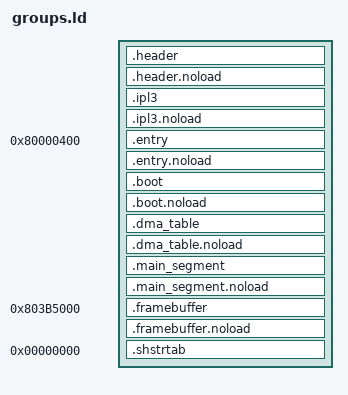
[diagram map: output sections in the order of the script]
SECTIONS
{
    __romPos = 0x0;

    header_ROM_START = __romPos;
    header_VRAM = ADDR(.header);
    header_alloc_VRAM = .;

    .header : AT(header_ROM_START) SUBALIGN(16)
    {
        FILL(0x00000000);
        header_TEXT_START = .;
        build/src/rom_header/rom_header.o(.text*);
        . = ALIGN(., 0x10);
        header_TEXT_END = .;
        header_TEXT_SIZE = ABSOLUTE(header_TEXT_END - header_TEXT_START);

        header_DATA_START = .;
        build/src/rom_header/rom_header.o(.data*);
        . = ALIGN(., 0x10);
        header_DATA_END = .;
        header_DATA_SIZE = ABSOLUTE(header_DATA_END - header_DATA_START);

        header_RODATA_START = .;
        build/src/rom_header/rom_header.o(.rodata*);
        . = ALIGN(., 0x10);
        header_RODATA_END = .;
        header_RODATA_SIZE = ABSOLUTE(header_RODATA_END - header_RODATA_START);

        header_SDATA_START = .;
        build/src/rom_header/rom_header.o(.sdata*);
        . = ALIGN(., 0x10);
        header_SDATA_END = .;
        header_SDATA_SIZE = ABSOLUTE(header_SDATA_END - header_SDATA_START);
    }

    header_alloc_VRAM_END = .;
    header_alloc_VRAM_SIZE = ABSOLUTE(header_alloc_VRAM_END - header_alloc_VRAM);

    header_noload_VRAM = .;

    .header.noload (NOLOAD) : SUBALIGN(16)
    {
        FILL(0x00000000);
        header_SBSS_START = .;
        build/src/rom_header/rom_header.o(.sbss*);
        . = ALIGN(., 0x10);
        header_SBSS_END = .;
        header_SBSS_SIZE = ABSOLUTE(header_SBSS_END - header_SBSS_START);

        header_SCOMMON_START = .;
        build/src/rom_header/rom_header.o(.scommon*);
        . = ALIGN(., 0x10);
        header_SCOMMON_END = .;
        header_SCOMMON_SIZE = ABSOLUTE(header_SCOMMON_END - header_SCOMMON_START);

        header_BSS_START = .;
        build/src/rom_header/rom_header.o(.bss*);
        . = ALIGN(., 0x10);
        header_BSS_END = .;
        header_BSS_SIZE = ABSOLUTE(header_BSS_END - header_BSS_START);

        headerCOMMON_START = .;
        build/src/rom_header/rom_header.o(COMMON*);
        . = ALIGN(., 0x10);
        headerCOMMON_END = .;
        headerCOMMON_SIZE = ABSOLUTE(headerCOMMON_END - headerCOMMON_START);
    }

    header_noload_VRAM_END = .;
    header_noload_VRAM_SIZE = ABSOLUTE(header_noload_VRAM_END - header_noload_VRAM);
    header_VRAM_END = .;
    header_VRAM_SIZE = ABSOLUTE(header_VRAM_END - header_VRAM);
    __romPos += SIZEOF(.header);
    header_ROM_END = __romPos;
    header_ROM_SIZE = ABSOLUTE(header_ROM_END - header_ROM_START);

    ipl3_ROM_START = __romPos;
    ipl3_VRAM = ADDR(.ipl3);
    ipl3_alloc_VRAM = .;

    .ipl3 : AT(ipl3_ROM_START) SUBALIGN(16)
    {
        FILL(0x00000000);
        ipl3_TEXT_START = .;
        build/asm/data/ipl3.o(.text*);
        . = ALIGN(., 0x10);
        ipl3_TEXT_END = .;
        ipl3_TEXT_SIZE = ABSOLUTE(ipl3_TEXT_END - ipl3_TEXT_START);

        ipl3_DATA_START = .;
        build/asm/data/ipl3.o(.data*);
        . = ALIGN(., 0x10);
        ipl3_DATA_END = .;
        ipl3_DATA_SIZE = ABSOLUTE(ipl3_DATA_END - ipl3_DATA_START);

        ipl3_RODATA_START = .;
        build/asm/data/ipl3.o(.rodata*);
        . = ALIGN(., 0x10);
        ipl3_RODATA_END = .;
        ipl3_RODATA_SIZE = ABSOLUTE(ipl3_RODATA_END - ipl3_RODATA_START);

        ipl3_SDATA_START = .;
        build/asm/data/ipl3.o(.sdata*);
        . = ALIGN(., 0x10);
        ipl3_SDATA_END = .;
        ipl3_SDATA_SIZE = ABSOLUTE(ipl3_SDATA_END - ipl3_SDATA_START);
    }

    ipl3_alloc_VRAM_END = .;
    ipl3_alloc_VRAM_SIZE = ABSOLUTE(ipl3_alloc_VRAM_END - ipl3_alloc_VRAM);

    ipl3_noload_VRAM = .;

    .ipl3.noload (NOLOAD) : SUBALIGN(16)
    {
        FILL(0x00000000);
        ipl3_SBSS_START = .;
        build/asm/data/ipl3.o(.sbss*);
        . = ALIGN(., 0x10);
        ipl3_SBSS_END = .;
        ipl3_SBSS_SIZE = ABSOLUTE(ipl3_SBSS_END - ipl3_SBSS_START);

        ipl3_SCOMMON_START = .;
        build/asm/data/ipl3.o(.scommon*);
        . = ALIGN(., 0x10);
        ipl3_SCOMMON_END = .;
        ipl3_SCOMMON_SIZE = ABSOLUTE(ipl3_SCOMMON_END - ipl3_SCOMMON_START);

        ipl3_BSS_START = .;
        build/asm/data/ipl3.o(.bss*);
        . = ALIGN(., 0x10);
        ipl3_BSS_END = .;
        ipl3_BSS_SIZE = ABSOLUTE(ipl3_BSS_END - ipl3_BSS_START);

        ipl3COMMON_START = .;
        build/asm/data/ipl3.o(COMMON*);
        . = ALIGN(., 0x10);
        ipl3COMMON_END = .;
        ipl3COMMON_SIZE = ABSOLUTE(ipl3COMMON_END - ipl3COMMON_START);
    }

    ipl3_noload_VRAM_END = .;
    ipl3_noload_VRAM_SIZE = ABSOLUTE(ipl3_noload_VRAM_END - ipl3_noload_VRAM);
    ipl3_VRAM_END = .;
    ipl3_VRAM_SIZE = ABSOLUTE(ipl3_VRAM_END - ipl3_VRAM);
    __romPos += SIZEOF(.ipl3);
    ipl3_ROM_END = __romPos;
    ipl3_ROM_SIZE = ABSOLUTE(ipl3_ROM_END - ipl3_ROM_START);

    entry_ROM_START = __romPos;
    entry_VRAM = ADDR(.entry);
    entry_alloc_VRAM = .;

    .entry 0x80000400 : AT(entry_ROM_START) SUBALIGN(16)
    {
        FILL(0x00000000);
        entry_TEXT_START = .;
        build/src/entry/entry.o(.text*);
        . = ALIGN(., 0x10);
        entry_TEXT_END = .;
        entry_TEXT_SIZE = ABSOLUTE(entry_TEXT_END - entry_TEXT_START);

        entry_DATA_START = .;
        build/src/entry/entry.o(.data*);
        . = ALIGN(., 0x10);
        entry_DATA_END = .;
        entry_DATA_SIZE = ABSOLUTE(entry_DATA_END - entry_DATA_START);

        entry_RODATA_START = .;
        build/src/entry/entry.o(.rodata*);
        . = ALIGN(., 0x10);
        entry_RODATA_END = .;
        entry_RODATA_SIZE = ABSOLUTE(entry_RODATA_END - entry_RODATA_START);

        entry_SDATA_START = .;
        build/src/entry/entry.o(.sdata*);
        . = ALIGN(., 0x10);
        entry_SDATA_END = .;
        entry_SDATA_SIZE = ABSOLUTE(entry_SDATA_END - entry_SDATA_START);
    }

    entry_alloc_VRAM_END = .;
    entry_alloc_VRAM_SIZE = ABSOLUTE(entry_alloc_VRAM_END - entry_alloc_VRAM);

    entry_noload_VRAM = .;

    .entry.noload (NOLOAD) : SUBALIGN(16)
    {
        FILL(0x00000000);
        entry_SBSS_START = .;
        build/src/entry/entry.o(.sbss*);
        . = ALIGN(., 0x10);
        entry_SBSS_END = .;
        entry_SBSS_SIZE = ABSOLUTE(entry_SBSS_END - entry_SBSS_START);

        entry_SCOMMON_START = .;
        build/src/entry/entry.o(.scommon*);
        . = ALIGN(., 0x10);
        entry_SCOMMON_END = .;
        entry_SCOMMON_SIZE = ABSOLUTE(entry_SCOMMON_END - entry_SCOMMON_START);

        entry_BSS_START = .;
        build/src/entry/entry.o(.bss*);
        . = ALIGN(., 0x10);
        entry_BSS_END = .;
        entry_BSS_SIZE = ABSOLUTE(entry_BSS_END - entry_BSS_START);

        entryCOMMON_START = .;
        build/src/entry/entry.o(COMMON*);
        . = ALIGN(., 0x10);
        entryCOMMON_END = .;
        entryCOMMON_SIZE = ABSOLUTE(entryCOMMON_END - entryCOMMON_START);
    }

    entry_noload_VRAM_END = .;
    entry_noload_VRAM_SIZE = ABSOLUTE(entry_noload_VRAM_END - entry_noload_VRAM);
    entry_VRAM_END = .;
    entry_VRAM_SIZE = ABSOLUTE(entry_VRAM_END - entry_VRAM);
    __romPos += SIZEOF(.entry);
    entry_ROM_END = __romPos;
    entry_ROM_SIZE = ABSOLUTE(entry_ROM_END - entry_ROM_START);

    boot_ROM_START = __romPos;
    boot_VRAM = ADDR(.boot);
    boot_alloc_VRAM = .;

    .boot : AT(boot_ROM_START) SUBALIGN(16)
    {
        FILL(0x00000000);
        boot_TEXT_START = .;
        build/src/boot/boot_main.o(.text*);
        build/src/boot/util.o(.text*);
        build/src/libultra/io/conteepprobe.o(.text*);
        build/src/libultra/io/conteeplongwrite.o(.text*);
        build/src/libultra/io/conteeplongread.o(.text*);
        build/src/libultra/io/pimgr.o(.text*);
        build/src/libultra/io/epirawdma.o(.text*);
        build/src/libultra/io/epidma.o(.text*);
        build/src/libultra/io/cartrominit.o(.text*);
        build/src/libultra/io/devmgr.o(.text*);
        build/src/libultra/io/piacs.o(.text*);
        build/src/libultra/io/pidma.o(.text*);
        build/src/libultra/io/aigetlen.o(.text*);
        build/src/libultra/io/aigetstat.o(.text*);
        build/src/libultra/io/aisetfreq.o(.text*);
        build/src/libultra/io/aisetnextbuf.o(.text*);
        build/src/libultra/audio/env.o(.text*);
        build/src/libultra/audio/sl.o(.text*);
        build/src/libultra/audio/heapinit.o(.text*);
        build/src/libultra/audio/synthesizer.o(.text*);
        build/src/libultra/audio/syndelete.o(.text*);
        build/src/libultra/audio/synaddplayer.o(.text*);
        build/src/libultra/audio/synallocvoice.o(.text*);
        build/src/libultra/audio/synstopvoice.o(.text*);
        build/src/libultra/audio/synstartvoice.o(.text*);
        build/src/libultra/audio/synsetpitch.o(.text*);
        build/src/libultra/audio/synsetvol.o(.text*);
        build/src/libultra/audio/synsetfxmix.o(.text*);
        build/src/libultra/audio/synsetpan.o(.text*);
        build/src/libultra/audio/synallocfx.o(.text*);
        build/src/libultra/os/invaldcache.o(.text*);
        build/src/libultra/os/writebackdcacheall.o(.text*);
        build/src/libultra/io/contquery.o(.text*);
        build/src/libultra/io/contreaddata.o(.text*);
        build/src/libultra/io/controller.o(.text*);
        build/src/libultra/io/contsetch.o(.text*);
        build/src/libultra/os/virtualtophysical.o(.text*);
        build/src/libultra/gu/sqrtf.o(.text*);
        build/src/libultra/gu/cosf.o(.text*);
        build/src/libultra/gu/ortho.o(.text*);
        build/src/libultra/gu/perspective.o(.text*);
        build/src/libultra/gu/rotaterpy.o(.text*);
        build/src/libultra/gu/sinf.o(.text*);
        build/src/libultra/gu/sins.o(.text*);
        build/src/libultra/libc/bcmp.o(.text*);
        build/src/libultra/libc/bcopy.o(.text*);
        build/src/libultra/libc/bzero.o(.text*);
        build/src/libultra/libc/string.o(.text*);
        build/src/libultra/os/createmesgqueue.o(.text*);
        build/src/libultra/os/jammesg.o(.text*);
        build/src/libultra/os/recvmesg.o(.text*);
        build/src/libultra/os/sendmesg.o(.text*);
        build/src/libultra/os/seteventmesg.o(.text*);
        build/src/libultra/io/sptask.o(.text*);
        build/src/libultra/io/sptaskyield.o(.text*);
        build/src/libultra/io/sptaskyielded.o(.text*);
        build/src/libultra/sched/sched.o(.text*);
        build/src/libultra/io/sirawdma.o(.text*);
        build/src/libultra/io/siacs.o(.text*);
        build/src/libultra/os/createthread.o(.text*);
        build/src/libultra/os/getthreadpri.o(.text*);
        build/src/libultra/os/setthreadpri.o(.text*);
        build/src/libultra/os/startthread.o(.text*);
        build/src/libultra/os/stopthread.o(.text*);
        build/src/libultra/os/thread.o(.text*);
        build/src/libultra/os/yieldthread.o(.text*);
        build/src/libultra/os/gettime.o(.text*);
        build/src/libultra/os/settime.o(.text*);
        build/src/libultra/os/settimer.o(.text*);
        build/src/libultra/os/timerintr.o(.text*);
        build/src/libultra/os/probetlb.o(.text*);
        build/src/libultra/io/vigetcurrframebuf.o(.text*);
        build/src/libultra/io/vigetnextframebuf.o(.text*);
        build/src/libultra/io/vimgr.o(.text*);
        build/src/libultra/io/vitbl.o(.text*);
        build/src/libultra/io/visetevent.o(.text*);
        build/src/libultra/io/visetmode.o(.text*);
        build/src/libultra/io/visetspecial.o(.text*);
        build/src/libultra/io/visetyscale.o(.text*);
        build/src/libultra/io/viswapbuf.o(.text*);
        build/src/libultra/io/viswapcontext.o(.text*);
        build/src/libultra/io/viblack.o(.text*);
        build/src/libultra/mgu/mtxident.o(.text*);
        build/src/libultra/mgu/mtxidentf.o(.text*);
        build/src/libultra/mgu/mtxf2l.o(.text*);
        build/src/libultra/mgu/mtxl2f.o(.text*);
        build/src/libultra/mgu/mtxcatf.o(.text*);
        build/src/libultra/mgu/scale.o(.text*);
        build/src/libultra/mgu/scalef.o(.text*);
        build/src/libultra/mgu/translate.o(.text*);
        build/src/libultra/mgu/translatef.o(.text*);
        build/src/libultra/os/initialize.o(.text*);
        build/src/libultra/io/conteepread.o(.text*);
        build/src/libultra/io/conteepwrite.o(.text*);
        build/src/libultra/os/exceptasm.o(.text*);
        build/src/libultra/os/interrupt.o(.text*);
        build/src/libultra/os/setintmask.o(.text*);
        build/src/libultra/os/setglobalintmask.o(.text*);
        build/src/libultra/os/resetglobalintmask.o(.text*);
        build/src/libultra/io/pirawdma.o(.text*);
        build/src/libultra/io/pigetcmdq.o(.text*);
        build/src/libultra/io/epirawread.o(.text*);
        build/src/libultra/io/epirawwrite.o(.text*);
        build/src/libultra/io/ai.o(.text*);
        build/src/libultra/audio/drvrnew.o(.text*);
        build/src/libultra/audio/load.o(.text*);
        build/src/libultra/audio/auxbus.o(.text*);
        build/src/libultra/audio/filter.o(.text*);
        build/src/libultra/audio/mainbus.o(.text*);
        build/src/libultra/audio/resample.o(.text*);
        build/src/libultra/audio/reverb.o(.text*);
        build/src/libultra/audio/save.o(.text*);
        build/src/libultra/audio/heapalloc.o(.text*);
        build/src/libultra/audio/copy.o(.text*);
        build/src/libultra/os/invalicache.o(.text*);
        build/src/libultra/os/writebackdcache.o(.text*);
        build/src/libultra/io/dpsetnextbuf.o(.text*);
        build/src/libultra/os/getcause.o(.text*);
        build/src/libultra/os/getcount.o(.text*);
        build/src/libultra/os/getsr.o(.text*);
        build/src/libultra/os/setcompare.o(.text*);
        build/src/libultra/os/setfpccsr.o(.text*);
        build/src/libultra/os/setsr.o(.text*);
        build/src/libultra/os/setwatchlo.o(.text*);
        build/src/libultra/io/sp.o(.text*);
        build/src/libultra/io/spgetstat.o(.text*);
        build/src/libultra/io/spsetstat.o(.text*);
        build/src/libultra/io/spsetpc.o(.text*);
        build/src/libultra/io/sprawdma.o(.text*);
        build/src/libultra/io/sirawread.o(.text*);
        build/src/libultra/io/sirawwrite.o(.text*);
        build/src/libultra/os/destroythread.o(.text*);
        build/src/libultra/os/maptlbrdb.o(.text*);
        build/src/libultra/os/unmaptlball.o(.text*);
        build/src/libultra/io/vi.o(.text*);
        build/src/libultra/io/vigetcurrcontext.o(.text*);
        build/src/libultra/vimodes/vimodentsclan1.o(.text*);
        build/src/libultra/vimodes/vimodepallan1.o(.text*);
        build/src/libultra/vimodes/vimodempallan1.o(.text*);
        build/src/libultra/os/parameters.o(.text*);
        build/src/libultra/gu/libm_vals.o(.text*);
        build/src/libultra/io/dp.o(.text*);
        build/src/libultra/io/si.o(.text*);
        build/src/libkmc/fmod.o(.text*);
        build/src/libkmc/memmove.o(.text*);
        build/src/libkmc/memset.o(.text*);
        build/src/libkmc/modf.o(.text*);
        build/src/libkmc/rand.o(.text*);
        build/src/libkmc/strcpy.o(.text*);
        build/src/libkmc/mmuldi3.o(.text*);
        build/src/libkmc/ctype.o(.text*);
        . = ALIGN(., 0x10);
        boot_TEXT_END = .;
        boot_TEXT_SIZE = ABSOLUTE(boot_TEXT_END - boot_TEXT_START);

        boot_DATA_START = .;
        build/src/boot/boot_main.o(.data*);
        build/src/boot/util.o(.data*);
        build/src/libultra/io/conteepprobe.o(.data*);
        build/src/libultra/io/conteeplongwrite.o(.data*);
        build/src/libultra/io/conteeplongread.o(.data*);
        build/src/libultra/io/pimgr.o(.data*);
        build/src/libultra/io/epirawdma.o(.data*);
        build/src/libultra/io/epidma.o(.data*);
        build/src/libultra/io/cartrominit.o(.data*);
        build/src/libultra/io/devmgr.o(.data*);
        build/src/libultra/io/piacs.o(.data*);
        build/src/libultra/io/pidma.o(.data*);
        build/src/libultra/io/aigetlen.o(.data*);
        build/src/libultra/io/aigetstat.o(.data*);
        build/src/libultra/io/aisetfreq.o(.data*);
        build/src/libultra/io/aisetnextbuf.o(.data*);
        build/src/libultra/audio/env.o(.data*);
        build/src/libultra/audio/sl.o(.data*);
        build/src/libultra/audio/heapinit.o(.data*);
        build/src/libultra/audio/synthesizer.o(.data*);
        build/src/libultra/audio/syndelete.o(.data*);
        build/src/libultra/audio/synaddplayer.o(.data*);
        build/src/libultra/audio/synallocvoice.o(.data*);
        build/src/libultra/audio/synstopvoice.o(.data*);
        build/src/libultra/audio/synstartvoice.o(.data*);
        build/src/libultra/audio/synsetpitch.o(.data*);
        build/src/libultra/audio/synsetvol.o(.data*);
        build/src/libultra/audio/synsetfxmix.o(.data*);
        build/src/libultra/audio/synsetpan.o(.data*);
        build/src/libultra/audio/synallocfx.o(.data*);
        build/src/libultra/os/invaldcache.o(.data*);
        build/src/libultra/os/writebackdcacheall.o(.data*);
        build/src/libultra/io/contquery.o(.data*);
        build/src/libultra/io/contreaddata.o(.data*);
        build/src/libultra/io/controller.o(.data*);
        build/src/libultra/io/contsetch.o(.data*);
        build/src/libultra/os/virtualtophysical.o(.data*);
        build/src/libultra/gu/sqrtf.o(.data*);
        build/src/libultra/gu/cosf.o(.data*);
        build/src/libultra/gu/ortho.o(.data*);
        build/src/libultra/gu/perspective.o(.data*);
        build/src/libultra/gu/rotaterpy.o(.data*);
        build/src/libultra/gu/sinf.o(.data*);
        build/src/libultra/gu/sins.o(.data*);
        build/src/libultra/libc/bcmp.o(.data*);
        build/src/libultra/libc/bcopy.o(.data*);
        build/src/libultra/libc/bzero.o(.data*);
        build/src/libultra/libc/string.o(.data*);
        build/src/libultra/os/createmesgqueue.o(.data*);
        build/src/libultra/os/jammesg.o(.data*);
        build/src/libultra/os/recvmesg.o(.data*);
        build/src/libultra/os/sendmesg.o(.data*);
        build/src/libultra/os/seteventmesg.o(.data*);
        build/src/libultra/io/sptask.o(.data*);
        build/src/libultra/io/sptaskyield.o(.data*);
        build/src/libultra/io/sptaskyielded.o(.data*);
        build/src/libultra/sched/sched.o(.data*);
        build/src/libultra/io/sirawdma.o(.data*);
        build/src/libultra/io/siacs.o(.data*);
        build/src/libultra/os/createthread.o(.data*);
        build/src/libultra/os/getthreadpri.o(.data*);
        build/src/libultra/os/setthreadpri.o(.data*);
        build/src/libultra/os/startthread.o(.data*);
        build/src/libultra/os/stopthread.o(.data*);
        build/src/libultra/os/thread.o(.data*);
        build/src/libultra/os/yieldthread.o(.data*);
        build/src/libultra/os/gettime.o(.data*);
        build/src/libultra/os/settime.o(.data*);
        build/src/libultra/os/settimer.o(.data*);
        build/src/libultra/os/timerintr.o(.data*);
        build/src/libultra/os/probetlb.o(.data*);
        build/src/libultra/io/vigetcurrframebuf.o(.data*);
        build/src/libultra/io/vigetnextframebuf.o(.data*);
        build/src/libultra/io/vimgr.o(.data*);
        build/src/libultra/io/vitbl.o(.data*);
        build/src/libultra/io/visetevent.o(.data*);
        build/src/libultra/io/visetmode.o(.data*);
        build/src/libultra/io/visetspecial.o(.data*);
        build/src/libultra/io/visetyscale.o(.data*);
        build/src/libultra/io/viswapbuf.o(.data*);
        build/src/libultra/io/viswapcontext.o(.data*);
        build/src/libultra/io/viblack.o(.data*);
        build/src/libultra/mgu/mtxident.o(.data*);
        build/src/libultra/mgu/mtxidentf.o(.data*);
        build/src/libultra/mgu/mtxf2l.o(.data*);
        build/src/libultra/mgu/mtxl2f.o(.data*);
        build/src/libultra/mgu/mtxcatf.o(.data*);
        build/src/libultra/mgu/scale.o(.data*);
        build/src/libultra/mgu/scalef.o(.data*);
        build/src/libultra/mgu/translate.o(.data*);
        build/src/libultra/mgu/translatef.o(.data*);
        build/src/libultra/os/initialize.o(.data*);
        build/src/libultra/io/conteepread.o(.data*);
        build/src/libultra/io/conteepwrite.o(.data*);
        build/src/libultra/os/exceptasm.o(.data*);
        build/src/libultra/os/interrupt.o(.data*);
        build/src/libultra/os/setintmask.o(.data*);
        build/src/libultra/os/setglobalintmask.o(.data*);
        build/src/libultra/os/resetglobalintmask.o(.data*);
        build/src/libultra/io/pirawdma.o(.data*);
        build/src/libultra/io/pigetcmdq.o(.data*);
        build/src/libultra/io/epirawread.o(.data*);
        build/src/libultra/io/epirawwrite.o(.data*);
        build/src/libultra/io/ai.o(.data*);
        build/src/libultra/audio/drvrnew.o(.data*);
        build/src/libultra/audio/load.o(.data*);
        build/src/libultra/audio/auxbus.o(.data*);
        build/src/libultra/audio/filter.o(.data*);
        build/src/libultra/audio/mainbus.o(.data*);
        build/src/libultra/audio/resample.o(.data*);
        build/src/libultra/audio/reverb.o(.data*);
        build/src/libultra/audio/save.o(.data*);
        build/src/libultra/audio/heapalloc.o(.data*);
        build/src/libultra/audio/copy.o(.data*);
        build/src/libultra/os/invalicache.o(.data*);
        build/src/libultra/os/writebackdcache.o(.data*);
        build/src/libultra/io/dpsetnextbuf.o(.data*);
        build/src/libultra/os/getcause.o(.data*);
        build/src/libultra/os/getcount.o(.data*);
        build/src/libultra/os/getsr.o(.data*);
        build/src/libultra/os/setcompare.o(.data*);
        build/src/libultra/os/setfpccsr.o(.data*);
        build/src/libultra/os/setsr.o(.data*);
        build/src/libultra/os/setwatchlo.o(.data*);
        build/src/libultra/io/sp.o(.data*);
        build/src/libultra/io/spgetstat.o(.data*);
        build/src/libultra/io/spsetstat.o(.data*);
        build/src/libultra/io/spsetpc.o(.data*);
        build/src/libultra/io/sprawdma.o(.data*);
        build/src/libultra/io/sirawread.o(.data*);
        build/src/libultra/io/sirawwrite.o(.data*);
        build/src/libultra/os/destroythread.o(.data*);
        build/src/libultra/os/maptlbrdb.o(.data*);
        build/src/libultra/os/unmaptlball.o(.data*);
        build/src/libultra/io/vi.o(.data*);
        build/src/libultra/io/vigetcurrcontext.o(.data*);
        build/src/libultra/vimodes/vimodentsclan1.o(.data*);
        build/src/libultra/vimodes/vimodepallan1.o(.data*);
        build/src/libultra/vimodes/vimodempallan1.o(.data*);
        build/src/libultra/os/parameters.o(.data*);
        build/src/libultra/gu/libm_vals.o(.data*);
        build/src/libultra/io/dp.o(.data*);
        build/src/libultra/io/si.o(.data*);
        build/src/libkmc/fmod.o(.data*);
        build/src/libkmc/memmove.o(.data*);
        build/src/libkmc/memset.o(.data*);
        build/src/libkmc/modf.o(.data*);
        build/src/libkmc/rand.o(.data*);
        build/src/libkmc/strcpy.o(.data*);
        build/src/libkmc/mmuldi3.o(.data*);
        build/src/libkmc/ctype.o(.data*);
        . = ALIGN(., 0x10);
        boot_DATA_END = .;
        boot_DATA_SIZE = ABSOLUTE(boot_DATA_END - boot_DATA_START);

        boot_RODATA_START = .;
        build/src/boot/boot_main.o(.rodata*);
        build/src/boot/util.o(.rodata*);
        build/src/libultra/io/conteepprobe.o(.rodata*);
        build/src/libultra/io/conteeplongwrite.o(.rodata*);
        build/src/libultra/io/conteeplongread.o(.rodata*);
        build/src/libultra/io/pimgr.o(.rodata*);
        build/src/libultra/io/epirawdma.o(.rodata*);
        build/src/libultra/io/epidma.o(.rodata*);
        build/src/libultra/io/cartrominit.o(.rodata*);
        build/src/libultra/io/devmgr.o(.rodata*);
        build/src/libultra/io/piacs.o(.rodata*);
        build/src/libultra/io/pidma.o(.rodata*);
        build/src/libultra/io/aigetlen.o(.rodata*);
        build/src/libultra/io/aigetstat.o(.rodata*);
        build/src/libultra/io/aisetfreq.o(.rodata*);
        build/src/libultra/io/aisetnextbuf.o(.rodata*);
        build/src/libultra/audio/env.o(.rodata*);
        build/src/libultra/audio/sl.o(.rodata*);
        build/src/libultra/audio/heapinit.o(.rodata*);
        build/src/libultra/audio/synthesizer.o(.rodata*);
        build/src/libultra/audio/syndelete.o(.rodata*);
        build/src/libultra/audio/synaddplayer.o(.rodata*);
        build/src/libultra/audio/synallocvoice.o(.rodata*);
        build/src/libultra/audio/synstopvoice.o(.rodata*);
        build/src/libultra/audio/synstartvoice.o(.rodata*);
        build/src/libultra/audio/synsetpitch.o(.rodata*);
        build/src/libultra/audio/synsetvol.o(.rodata*);
        build/src/libultra/audio/synsetfxmix.o(.rodata*);
        build/src/libultra/audio/synsetpan.o(.rodata*);
        build/src/libultra/audio/synallocfx.o(.rodata*);
        build/src/libultra/os/invaldcache.o(.rodata*);
        build/src/libultra/os/writebackdcacheall.o(.rodata*);
        build/src/libultra/io/contquery.o(.rodata*);
        build/src/libultra/io/contreaddata.o(.rodata*);
        build/src/libultra/io/controller.o(.rodata*);
        build/src/libultra/io/contsetch.o(.rodata*);
        build/src/libultra/os/virtualtophysical.o(.rodata*);
        build/src/libultra/gu/sqrtf.o(.rodata*);
        build/src/libultra/gu/cosf.o(.rodata*);
        build/src/libultra/gu/ortho.o(.rodata*);
        build/src/libultra/gu/perspective.o(.rodata*);
        build/src/libultra/gu/rotaterpy.o(.rodata*);
        build/src/libultra/gu/sinf.o(.rodata*);
        build/src/libultra/gu/sins.o(.rodata*);
        build/src/libultra/libc/bcmp.o(.rodata*);
        build/src/libultra/libc/bcopy.o(.rodata*);
        build/src/libultra/libc/bzero.o(.rodata*);
        build/src/libultra/libc/string.o(.rodata*);
        build/src/libultra/os/createmesgqueue.o(.rodata*);
        build/src/libultra/os/jammesg.o(.rodata*);
        build/src/libultra/os/recvmesg.o(.rodata*);
        build/src/libultra/os/sendmesg.o(.rodata*);
        build/src/libultra/os/seteventmesg.o(.rodata*);
        build/src/libultra/io/sptask.o(.rodata*);
        build/src/libultra/io/sptaskyield.o(.rodata*);
        build/src/libultra/io/sptaskyielded.o(.rodata*);
        build/src/libultra/sched/sched.o(.rodata*);
        build/src/libultra/io/sirawdma.o(.rodata*);
        build/src/libultra/io/siacs.o(.rodata*);
        build/src/libultra/os/createthread.o(.rodata*);
        build/src/libultra/os/getthreadpri.o(.rodata*);
        build/src/libultra/os/setthreadpri.o(.rodata*);
        build/src/libultra/os/startthread.o(.rodata*);
        build/src/libultra/os/stopthread.o(.rodata*);
        build/src/libultra/os/thread.o(.rodata*);
        build/src/libultra/os/yieldthread.o(.rodata*);
        build/src/libultra/os/gettime.o(.rodata*);
        build/src/libultra/os/settime.o(.rodata*);
        build/src/libultra/os/settimer.o(.rodata*);
        build/src/libultra/os/timerintr.o(.rodata*);
        build/src/libultra/os/probetlb.o(.rodata*);
        build/src/libultra/io/vigetcurrframebuf.o(.rodata*);
        build/src/libultra/io/vigetnextframebuf.o(.rodata*);
        build/src/libultra/io/vimgr.o(.rodata*);
        build/src/libultra/io/vitbl.o(.rodata*);
        build/src/libultra/io/visetevent.o(.rodata*);
        build/src/libultra/io/visetmode.o(.rodata*);
        build/src/libultra/io/visetspecial.o(.rodata*);
        build/src/libultra/io/visetyscale.o(.rodata*);
        build/src/libultra/io/viswapbuf.o(.rodata*);
        build/src/libultra/io/viswapcontext.o(.rodata*);
        build/src/libultra/io/viblack.o(.rodata*);
        build/src/libultra/mgu/mtxident.o(.rodata*);
        build/src/libultra/mgu/mtxidentf.o(.rodata*);
        build/src/libultra/mgu/mtxf2l.o(.rodata*);
        build/src/libultra/mgu/mtxl2f.o(.rodata*);
        build/src/libultra/mgu/mtxcatf.o(.rodata*);
        build/src/libultra/mgu/scale.o(.rodata*);
        build/src/libultra/mgu/scalef.o(.rodata*);
        build/src/libultra/mgu/translate.o(.rodata*);
        build/src/libultra/mgu/translatef.o(.rodata*);
        build/src/libultra/os/initialize.o(.rodata*);
        build/src/libultra/io/conteepread.o(.rodata*);
        build/src/libultra/io/conteepwrite.o(.rodata*);
        build/src/libultra/os/exceptasm.o(.rodata*);
        build/src/libultra/os/interrupt.o(.rodata*);
        build/src/libultra/os/setintmask.o(.rodata*);
        build/src/libultra/os/setglobalintmask.o(.rodata*);
        build/src/libultra/os/resetglobalintmask.o(.rodata*);
        build/src/libultra/io/pirawdma.o(.rodata*);
        build/src/libultra/io/pigetcmdq.o(.rodata*);
        build/src/libultra/io/epirawread.o(.rodata*);
        build/src/libultra/io/epirawwrite.o(.rodata*);
        build/src/libultra/io/ai.o(.rodata*);
        build/src/libultra/audio/drvrnew.o(.rodata*);
        build/src/libultra/audio/load.o(.rodata*);
        build/src/libultra/audio/auxbus.o(.rodata*);
        build/src/libultra/audio/filter.o(.rodata*);
        build/src/libultra/audio/mainbus.o(.rodata*);
        build/src/libultra/audio/resample.o(.rodata*);
        build/src/libultra/audio/reverb.o(.rodata*);
        build/src/libultra/audio/save.o(.rodata*);
        build/src/libultra/audio/heapalloc.o(.rodata*);
        build/src/libultra/audio/copy.o(.rodata*);
        build/src/libultra/os/invalicache.o(.rodata*);
        build/src/libultra/os/writebackdcache.o(.rodata*);
        build/src/libultra/io/dpsetnextbuf.o(.rodata*);
        build/src/libultra/os/getcause.o(.rodata*);
        build/src/libultra/os/getcount.o(.rodata*);
        build/src/libultra/os/getsr.o(.rodata*);
        build/src/libultra/os/setcompare.o(.rodata*);
        build/src/libultra/os/setfpccsr.o(.rodata*);
        build/src/libultra/os/setsr.o(.rodata*);
        build/src/libultra/os/setwatchlo.o(.rodata*);
        build/src/libultra/io/sp.o(.rodata*);
        build/src/libultra/io/spgetstat.o(.rodata*);
        build/src/libultra/io/spsetstat.o(.rodata*);
        build/src/libultra/io/spsetpc.o(.rodata*);
        build/src/libultra/io/sprawdma.o(.rodata*);
        build/src/libultra/io/sirawread.o(.rodata*);
        build/src/libultra/io/sirawwrite.o(.rodata*);
        build/src/libultra/os/destroythread.o(.rodata*);
        build/src/libultra/os/maptlbrdb.o(.rodata*);
        build/src/libultra/os/unmaptlball.o(.rodata*);
        build/src/libultra/io/vi.o(.rodata*);
        build/src/libultra/io/vigetcurrcontext.o(.rodata*);
        build/src/libultra/vimodes/vimodentsclan1.o(.rodata*);
        build/src/libultra/vimodes/vimodepallan1.o(.rodata*);
        build/src/libultra/vimodes/vimodempallan1.o(.rodata*);
        build/src/libultra/os/parameters.o(.rodata*);
        build/src/libultra/gu/libm_vals.o(.rodata*);
        build/src/libultra/io/dp.o(.rodata*);
        build/src/libultra/io/si.o(.rodata*);
        build/src/libkmc/fmod.o(.rodata*);
        build/src/libkmc/memmove.o(.rodata*);
        build/src/libkmc/memset.o(.rodata*);
        build/src/libkmc/modf.o(.rodata*);
        build/src/libkmc/rand.o(.rodata*);
        build/src/libkmc/strcpy.o(.rodata*);
        build/src/libkmc/mmuldi3.o(.rodata*);
        build/src/libkmc/ctype.o(.rodata*);
        . = ALIGN(., 0x10);
        boot_RODATA_END = .;
        boot_RODATA_SIZE = ABSOLUTE(boot_RODATA_END - boot_RODATA_START);

        boot_SDATA_START = .;
        build/src/boot/boot_main.o(.sdata*);
        build/src/boot/util.o(.sdata*);
        build/src/libultra/io/conteepprobe.o(.sdata*);
        build/src/libultra/io/conteeplongwrite.o(.sdata*);
        build/src/libultra/io/conteeplongread.o(.sdata*);
        build/src/libultra/io/pimgr.o(.sdata*);
        build/src/libultra/io/epirawdma.o(.sdata*);
        build/src/libultra/io/epidma.o(.sdata*);
        build/src/libultra/io/cartrominit.o(.sdata*);
        build/src/libultra/io/devmgr.o(.sdata*);
        build/src/libultra/io/piacs.o(.sdata*);
        build/src/libultra/io/pidma.o(.sdata*);
        build/src/libultra/io/aigetlen.o(.sdata*);
        build/src/libultra/io/aigetstat.o(.sdata*);
        build/src/libultra/io/aisetfreq.o(.sdata*);
        build/src/libultra/io/aisetnextbuf.o(.sdata*);
        build/src/libultra/audio/env.o(.sdata*);
        build/src/libultra/audio/sl.o(.sdata*);
        build/src/libultra/audio/heapinit.o(.sdata*);
        build/src/libultra/audio/synthesizer.o(.sdata*);
        build/src/libultra/audio/syndelete.o(.sdata*);
        build/src/libultra/audio/synaddplayer.o(.sdata*);
        build/src/libultra/audio/synallocvoice.o(.sdata*);
        build/src/libultra/audio/synstopvoice.o(.sdata*);
        build/src/libultra/audio/synstartvoice.o(.sdata*);
        build/src/libultra/audio/synsetpitch.o(.sdata*);
        build/src/libultra/audio/synsetvol.o(.sdata*);
        build/src/libultra/audio/synsetfxmix.o(.sdata*);
        build/src/libultra/audio/synsetpan.o(.sdata*);
        build/src/libultra/audio/synallocfx.o(.sdata*);
        build/src/libultra/os/invaldcache.o(.sdata*);
        build/src/libultra/os/writebackdcacheall.o(.sdata*);
        build/src/libultra/io/contquery.o(.sdata*);
        build/src/libultra/io/contreaddata.o(.sdata*);
        build/src/libultra/io/controller.o(.sdata*);
        build/src/libultra/io/contsetch.o(.sdata*);
        build/src/libultra/os/virtualtophysical.o(.sdata*);
        build/src/libultra/gu/sqrtf.o(.sdata*);
        build/src/libultra/gu/cosf.o(.sdata*);
        build/src/libultra/gu/ortho.o(.sdata*);
        build/src/libultra/gu/perspective.o(.sdata*);
        build/src/libultra/gu/rotaterpy.o(.sdata*);
        build/src/libultra/gu/sinf.o(.sdata*);
        build/src/libultra/gu/sins.o(.sdata*);
        build/src/libultra/libc/bcmp.o(.sdata*);
        build/src/libultra/libc/bcopy.o(.sdata*);
        build/src/libultra/libc/bzero.o(.sdata*);
        build/src/libultra/libc/string.o(.sdata*);
        build/src/libultra/os/createmesgqueue.o(.sdata*);
        build/src/libultra/os/jammesg.o(.sdata*);
        build/src/libultra/os/recvmesg.o(.sdata*);
        build/src/libultra/os/sendmesg.o(.sdata*);
        build/src/libultra/os/seteventmesg.o(.sdata*);
        build/src/libultra/io/sptask.o(.sdata*);
        build/src/libultra/io/sptaskyield.o(.sdata*);
        build/src/libultra/io/sptaskyielded.o(.sdata*);
        build/src/libultra/sched/sched.o(.sdata*);
        build/src/libultra/io/sirawdma.o(.sdata*);
        build/src/libultra/io/siacs.o(.sdata*);
        build/src/libultra/os/createthread.o(.sdata*);
        build/src/libultra/os/getthreadpri.o(.sdata*);
        build/src/libultra/os/setthreadpri.o(.sdata*);
        build/src/libultra/os/startthread.o(.sdata*);
        build/src/libultra/os/stopthread.o(.sdata*);
        build/src/libultra/os/thread.o(.sdata*);
        build/src/libultra/os/yieldthread.o(.sdata*);
        build/src/libultra/os/gettime.o(.sdata*);
        build/src/libultra/os/settime.o(.sdata*);
        build/src/libultra/os/settimer.o(.sdata*);
        build/src/libultra/os/timerintr.o(.sdata*);
        build/src/libultra/os/probetlb.o(.sdata*);
        build/src/libultra/io/vigetcurrframebuf.o(.sdata*);
        build/src/libultra/io/vigetnextframebuf.o(.sdata*);
        build/src/libultra/io/vimgr.o(.sdata*);
        build/src/libultra/io/vitbl.o(.sdata*);
        build/src/libultra/io/visetevent.o(.sdata*);
        build/src/libultra/io/visetmode.o(.sdata*);
        build/src/libultra/io/visetspecial.o(.sdata*);
        build/src/libultra/io/visetyscale.o(.sdata*);
        build/src/libultra/io/viswapbuf.o(.sdata*);
        build/src/libultra/io/viswapcontext.o(.sdata*);
        build/src/libultra/io/viblack.o(.sdata*);
        build/src/libultra/mgu/mtxident.o(.sdata*);
        build/src/libultra/mgu/mtxidentf.o(.sdata*);
        build/src/libultra/mgu/mtxf2l.o(.sdata*);
        build/src/libultra/mgu/mtxl2f.o(.sdata*);
        build/src/libultra/mgu/mtxcatf.o(.sdata*);
        build/src/libultra/mgu/scale.o(.sdata*);
        build/src/libultra/mgu/scalef.o(.sdata*);
        build/src/libultra/mgu/translate.o(.sdata*);
        build/src/libultra/mgu/translatef.o(.sdata*);
        build/src/libultra/os/initialize.o(.sdata*);
        build/src/libultra/io/conteepread.o(.sdata*);
        build/src/libultra/io/conteepwrite.o(.sdata*);
        build/src/libultra/os/exceptasm.o(.sdata*);
        build/src/libultra/os/interrupt.o(.sdata*);
        build/src/libultra/os/setintmask.o(.sdata*);
        build/src/libultra/os/setglobalintmask.o(.sdata*);
        build/src/libultra/os/resetglobalintmask.o(.sdata*);
        build/src/libultra/io/pirawdma.o(.sdata*);
        build/src/libultra/io/pigetcmdq.o(.sdata*);
        build/src/libultra/io/epirawread.o(.sdata*);
        build/src/libultra/io/epirawwrite.o(.sdata*);
        build/src/libultra/io/ai.o(.sdata*);
        build/src/libultra/audio/drvrnew.o(.sdata*);
        build/src/libultra/audio/load.o(.sdata*);
        build/src/libultra/audio/auxbus.o(.sdata*);
        build/src/libultra/audio/filter.o(.sdata*);
        build/src/libultra/audio/mainbus.o(.sdata*);
        build/src/libultra/audio/resample.o(.sdata*);
        build/src/libultra/audio/reverb.o(.sdata*);
        build/src/libultra/audio/save.o(.sdata*);
        build/src/libultra/audio/heapalloc.o(.sdata*);
        build/src/libultra/audio/copy.o(.sdata*);
        build/src/libultra/os/invalicache.o(.sdata*);
        build/src/libultra/os/writebackdcache.o(.sdata*);
        build/src/libultra/io/dpsetnextbuf.o(.sdata*);
        build/src/libultra/os/getcause.o(.sdata*);
        build/src/libultra/os/getcount.o(.sdata*);
        build/src/libultra/os/getsr.o(.sdata*);
        build/src/libultra/os/setcompare.o(.sdata*);
        build/src/libultra/os/setfpccsr.o(.sdata*);
        build/src/libultra/os/setsr.o(.sdata*);
        build/src/libultra/os/setwatchlo.o(.sdata*);
        build/src/libultra/io/sp.o(.sdata*);
        build/src/libultra/io/spgetstat.o(.sdata*);
        build/src/libultra/io/spsetstat.o(.sdata*);
        build/src/libultra/io/spsetpc.o(.sdata*);
        build/src/libultra/io/sprawdma.o(.sdata*);
        build/src/libultra/io/sirawread.o(.sdata*);
        build/src/libultra/io/sirawwrite.o(.sdata*);
        build/src/libultra/os/destroythread.o(.sdata*);
        build/src/libultra/os/maptlbrdb.o(.sdata*);
        build/src/libultra/os/unmaptlball.o(.sdata*);
        build/src/libultra/io/vi.o(.sdata*);
        build/src/libultra/io/vigetcurrcontext.o(.sdata*);
        build/src/libultra/vimodes/vimodentsclan1.o(.sdata*);
        build/src/libultra/vimodes/vimodepallan1.o(.sdata*);
        build/src/libultra/vimodes/vimodempallan1.o(.sdata*);
        build/src/libultra/os/parameters.o(.sdata*);
        build/src/libultra/gu/libm_vals.o(.sdata*);
        build/src/libultra/io/dp.o(.sdata*);
        build/src/libultra/io/si.o(.sdata*);
        build/src/libkmc/fmod.o(.sdata*);
        build/src/libkmc/memmove.o(.sdata*);
        build/src/libkmc/memset.o(.sdata*);
        build/src/libkmc/modf.o(.sdata*);
        build/src/libkmc/rand.o(.sdata*);
        build/src/libkmc/strcpy.o(.sdata*);
        build/src/libkmc/mmuldi3.o(.sdata*);
        build/src/libkmc/ctype.o(.sdata*);
        . = ALIGN(., 0x10);
        boot_SDATA_END = .;
        boot_SDATA_SIZE = ABSOLUTE(boot_SDATA_END - boot_SDATA_START);
    }

    boot_alloc_VRAM_END = .;
    boot_alloc_VRAM_SIZE = ABSOLUTE(boot_alloc_VRAM_END - boot_alloc_VRAM);

    boot_noload_VRAM = .;

    .boot.noload (NOLOAD) : SUBALIGN(16)
    {
        FILL(0x00000000);
        boot_SBSS_START = .;
        build/src/boot/boot_main.o(.sbss*);
        build/src/boot/util.o(.sbss*);
        build/src/libultra/io/conteepprobe.o(.sbss*);
        build/src/libultra/io/conteeplongwrite.o(.sbss*);
        build/src/libultra/io/conteeplongread.o(.sbss*);
        build/src/libultra/io/pimgr.o(.sbss*);
        build/src/libultra/io/epirawdma.o(.sbss*);
        build/src/libultra/io/epidma.o(.sbss*);
        build/src/libultra/io/cartrominit.o(.sbss*);
        build/src/libultra/io/devmgr.o(.sbss*);
        build/src/libultra/io/piacs.o(.sbss*);
        build/src/libultra/io/pidma.o(.sbss*);
        build/src/libultra/io/aigetlen.o(.sbss*);
        build/src/libultra/io/aigetstat.o(.sbss*);
        build/src/libultra/io/aisetfreq.o(.sbss*);
        build/src/libultra/io/aisetnextbuf.o(.sbss*);
        build/src/libultra/audio/env.o(.sbss*);
        build/src/libultra/audio/sl.o(.sbss*);
        build/src/libultra/audio/heapinit.o(.sbss*);
        build/src/libultra/audio/synthesizer.o(.sbss*);
        build/src/libultra/audio/syndelete.o(.sbss*);
        build/src/libultra/audio/synaddplayer.o(.sbss*);
        build/src/libultra/audio/synallocvoice.o(.sbss*);
        build/src/libultra/audio/synstopvoice.o(.sbss*);
        build/src/libultra/audio/synstartvoice.o(.sbss*);
        build/src/libultra/audio/synsetpitch.o(.sbss*);
        build/src/libultra/audio/synsetvol.o(.sbss*);
        build/src/libultra/audio/synsetfxmix.o(.sbss*);
        build/src/libultra/audio/synsetpan.o(.sbss*);
        build/src/libultra/audio/synallocfx.o(.sbss*);
        build/src/libultra/os/invaldcache.o(.sbss*);
        build/src/libultra/os/writebackdcacheall.o(.sbss*);
        build/src/libultra/io/contquery.o(.sbss*);
        build/src/libultra/io/contreaddata.o(.sbss*);
        build/src/libultra/io/controller.o(.sbss*);
        build/src/libultra/io/contsetch.o(.sbss*);
        build/src/libultra/os/virtualtophysical.o(.sbss*);
        build/src/libultra/gu/sqrtf.o(.sbss*);
        build/src/libultra/gu/cosf.o(.sbss*);
        build/src/libultra/gu/ortho.o(.sbss*);
        build/src/libultra/gu/perspective.o(.sbss*);
        build/src/libultra/gu/rotaterpy.o(.sbss*);
        build/src/libultra/gu/sinf.o(.sbss*);
        build/src/libultra/gu/sins.o(.sbss*);
        build/src/libultra/libc/bcmp.o(.sbss*);
        build/src/libultra/libc/bcopy.o(.sbss*);
        build/src/libultra/libc/bzero.o(.sbss*);
        build/src/libultra/libc/string.o(.sbss*);
        build/src/libultra/os/createmesgqueue.o(.sbss*);
        build/src/libultra/os/jammesg.o(.sbss*);
        build/src/libultra/os/recvmesg.o(.sbss*);
        build/src/libultra/os/sendmesg.o(.sbss*);
        build/src/libultra/os/seteventmesg.o(.sbss*);
        build/src/libultra/io/sptask.o(.sbss*);
        build/src/libultra/io/sptaskyield.o(.sbss*);
        build/src/libultra/io/sptaskyielded.o(.sbss*);
        build/src/libultra/sched/sched.o(.sbss*);
        build/src/libultra/io/sirawdma.o(.sbss*);
        build/src/libultra/io/siacs.o(.sbss*);
        build/src/libultra/os/createthread.o(.sbss*);
        build/src/libultra/os/getthreadpri.o(.sbss*);
        build/src/libultra/os/setthreadpri.o(.sbss*);
        build/src/libultra/os/startthread.o(.sbss*);
        build/src/libultra/os/stopthread.o(.sbss*);
        build/src/libultra/os/thread.o(.sbss*);
        build/src/libultra/os/yieldthread.o(.sbss*);
        build/src/libultra/os/gettime.o(.sbss*);
        build/src/libultra/os/settime.o(.sbss*);
        build/src/libultra/os/settimer.o(.sbss*);
        build/src/libultra/os/timerintr.o(.sbss*);
        build/src/libultra/os/probetlb.o(.sbss*);
        build/src/libultra/io/vigetcurrframebuf.o(.sbss*);
        build/src/libultra/io/vigetnextframebuf.o(.sbss*);
        build/src/libultra/io/vimgr.o(.sbss*);
        build/src/libultra/io/vitbl.o(.sbss*);
        build/src/libultra/io/visetevent.o(.sbss*);
        build/src/libultra/io/visetmode.o(.sbss*);
        build/src/libultra/io/visetspecial.o(.sbss*);
        build/src/libultra/io/visetyscale.o(.sbss*);
        build/src/libultra/io/viswapbuf.o(.sbss*);
        build/src/libultra/io/viswapcontext.o(.sbss*);
        build/src/libultra/io/viblack.o(.sbss*);
        build/src/libultra/mgu/mtxident.o(.sbss*);
        build/src/libultra/mgu/mtxidentf.o(.sbss*);
        build/src/libultra/mgu/mtxf2l.o(.sbss*);
        build/src/libultra/mgu/mtxl2f.o(.sbss*);
        build/src/libultra/mgu/mtxcatf.o(.sbss*);
        build/src/libultra/mgu/scale.o(.sbss*);
        build/src/libultra/mgu/scalef.o(.sbss*);
        build/src/libultra/mgu/translate.o(.sbss*);
        build/src/libultra/mgu/translatef.o(.sbss*);
        build/src/libultra/os/initialize.o(.sbss*);
        build/src/libultra/io/conteepread.o(.sbss*);
        build/src/libultra/io/conteepwrite.o(.sbss*);
        build/src/libultra/os/exceptasm.o(.sbss*);
        build/src/libultra/os/interrupt.o(.sbss*);
        build/src/libultra/os/setintmask.o(.sbss*);
        build/src/libultra/os/setglobalintmask.o(.sbss*);
        build/src/libultra/os/resetglobalintmask.o(.sbss*);
        build/src/libultra/io/pirawdma.o(.sbss*);
        build/src/libultra/io/pigetcmdq.o(.sbss*);
        build/src/libultra/io/epirawread.o(.sbss*);
        build/src/libultra/io/epirawwrite.o(.sbss*);
        build/src/libultra/io/ai.o(.sbss*);
        build/src/libultra/audio/drvrnew.o(.sbss*);
        build/src/libultra/audio/load.o(.sbss*);
        build/src/libultra/audio/auxbus.o(.sbss*);
        build/src/libultra/audio/filter.o(.sbss*);
        build/src/libultra/audio/mainbus.o(.sbss*);
        build/src/libultra/audio/resample.o(.sbss*);
        build/src/libultra/audio/reverb.o(.sbss*);
        build/src/libultra/audio/save.o(.sbss*);
        build/src/libultra/audio/heapalloc.o(.sbss*);
        build/src/libultra/audio/copy.o(.sbss*);
        build/src/libultra/os/invalicache.o(.sbss*);
        build/src/libultra/os/writebackdcache.o(.sbss*);
        build/src/libultra/io/dpsetnextbuf.o(.sbss*);
        build/src/libultra/os/getcause.o(.sbss*);
        build/src/libultra/os/getcount.o(.sbss*);
        build/src/libultra/os/getsr.o(.sbss*);
        build/src/libultra/os/setcompare.o(.sbss*);
        build/src/libultra/os/setfpccsr.o(.sbss*);
        build/src/libultra/os/setsr.o(.sbss*);
        build/src/libultra/os/setwatchlo.o(.sbss*);
        build/src/libultra/io/sp.o(.sbss*);
        build/src/libultra/io/spgetstat.o(.sbss*);
        build/src/libultra/io/spsetstat.o(.sbss*);
        build/src/libultra/io/spsetpc.o(.sbss*);
        build/src/libultra/io/sprawdma.o(.sbss*);
        build/src/libultra/io/sirawread.o(.sbss*);
        build/src/libultra/io/sirawwrite.o(.sbss*);
        build/src/libultra/os/destroythread.o(.sbss*);
        build/src/libultra/os/maptlbrdb.o(.sbss*);
        build/src/libultra/os/unmaptlball.o(.sbss*);
        build/src/libultra/io/vi.o(.sbss*);
        build/src/libultra/io/vigetcurrcontext.o(.sbss*);
        build/src/libultra/vimodes/vimodentsclan1.o(.sbss*);
        build/src/libultra/vimodes/vimodepallan1.o(.sbss*);
        build/src/libultra/vimodes/vimodempallan1.o(.sbss*);
        build/src/libultra/os/parameters.o(.sbss*);
        build/src/libultra/gu/libm_vals.o(.sbss*);
        build/src/libultra/io/dp.o(.sbss*);
        build/src/libultra/io/si.o(.sbss*);
        build/src/libkmc/fmod.o(.sbss*);
        build/src/libkmc/memmove.o(.sbss*);
        build/src/libkmc/memset.o(.sbss*);
        build/src/libkmc/modf.o(.sbss*);
        build/src/libkmc/rand.o(.sbss*);
        build/src/libkmc/strcpy.o(.sbss*);
        build/src/libkmc/mmuldi3.o(.sbss*);
        build/src/libkmc/ctype.o(.sbss*);
        . = ALIGN(., 0x10);
        boot_SBSS_END = .;
        boot_SBSS_SIZE = ABSOLUTE(boot_SBSS_END - boot_SBSS_START);

        boot_SCOMMON_START = .;
        build/src/boot/boot_main.o(.scommon*);
        build/src/boot/util.o(.scommon*);
        build/src/libultra/io/conteepprobe.o(.scommon*);
        build/src/libultra/io/conteeplongwrite.o(.scommon*);
        build/src/libultra/io/conteeplongread.o(.scommon*);
        build/src/libultra/io/pimgr.o(.scommon*);
        build/src/libultra/io/epirawdma.o(.scommon*);
        build/src/libultra/io/epidma.o(.scommon*);
        build/src/libultra/io/cartrominit.o(.scommon*);
        build/src/libultra/io/devmgr.o(.scommon*);
        build/src/libultra/io/piacs.o(.scommon*);
        build/src/libultra/io/pidma.o(.scommon*);
        build/src/libultra/io/aigetlen.o(.scommon*);
        build/src/libultra/io/aigetstat.o(.scommon*);
        build/src/libultra/io/aisetfreq.o(.scommon*);
        build/src/libultra/io/aisetnextbuf.o(.scommon*);
        build/src/libultra/audio/env.o(.scommon*);
        build/src/libultra/audio/sl.o(.scommon*);
        build/src/libultra/audio/heapinit.o(.scommon*);
        build/src/libultra/audio/synthesizer.o(.scommon*);
        build/src/libultra/audio/syndelete.o(.scommon*);
        build/src/libultra/audio/synaddplayer.o(.scommon*);
        build/src/libultra/audio/synallocvoice.o(.scommon*);
        build/src/libultra/audio/synstopvoice.o(.scommon*);
        build/src/libultra/audio/synstartvoice.o(.scommon*);
        build/src/libultra/audio/synsetpitch.o(.scommon*);
        build/src/libultra/audio/synsetvol.o(.scommon*);
        build/src/libultra/audio/synsetfxmix.o(.scommon*);
        build/src/libultra/audio/synsetpan.o(.scommon*);
        build/src/libultra/audio/synallocfx.o(.scommon*);
        build/src/libultra/os/invaldcache.o(.scommon*);
        build/src/libultra/os/writebackdcacheall.o(.scommon*);
        build/src/libultra/io/contquery.o(.scommon*);
        build/src/libultra/io/contreaddata.o(.scommon*);
        build/src/libultra/io/controller.o(.scommon*);
        build/src/libultra/io/contsetch.o(.scommon*);
        build/src/libultra/os/virtualtophysical.o(.scommon*);
        build/src/libultra/gu/sqrtf.o(.scommon*);
        build/src/libultra/gu/cosf.o(.scommon*);
        build/src/libultra/gu/ortho.o(.scommon*);
        build/src/libultra/gu/perspective.o(.scommon*);
        build/src/libultra/gu/rotaterpy.o(.scommon*);
        build/src/libultra/gu/sinf.o(.scommon*);
        build/src/libultra/gu/sins.o(.scommon*);
        build/src/libultra/libc/bcmp.o(.scommon*);
        build/src/libultra/libc/bcopy.o(.scommon*);
        build/src/libultra/libc/bzero.o(.scommon*);
        build/src/libultra/libc/string.o(.scommon*);
        build/src/libultra/os/createmesgqueue.o(.scommon*);
        build/src/libultra/os/jammesg.o(.scommon*);
        build/src/libultra/os/recvmesg.o(.scommon*);
        build/src/libultra/os/sendmesg.o(.scommon*);
        build/src/libultra/os/seteventmesg.o(.scommon*);
        build/src/libultra/io/sptask.o(.scommon*);
        build/src/libultra/io/sptaskyield.o(.scommon*);
        build/src/libultra/io/sptaskyielded.o(.scommon*);
        build/src/libultra/sched/sched.o(.scommon*);
        build/src/libultra/io/sirawdma.o(.scommon*);
        build/src/libultra/io/siacs.o(.scommon*);
        build/src/libultra/os/createthread.o(.scommon*);
        build/src/libultra/os/getthreadpri.o(.scommon*);
        build/src/libultra/os/setthreadpri.o(.scommon*);
        build/src/libultra/os/startthread.o(.scommon*);
        build/src/libultra/os/stopthread.o(.scommon*);
        build/src/libultra/os/thread.o(.scommon*);
        build/src/libultra/os/yieldthread.o(.scommon*);
        build/src/libultra/os/gettime.o(.scommon*);
        build/src/libultra/os/settime.o(.scommon*);
        build/src/libultra/os/settimer.o(.scommon*);
        build/src/libultra/os/timerintr.o(.scommon*);
        build/src/libultra/os/probetlb.o(.scommon*);
        build/src/libultra/io/vigetcurrframebuf.o(.scommon*);
        build/src/libultra/io/vigetnextframebuf.o(.scommon*);
        build/src/libultra/io/vimgr.o(.scommon*);
        build/src/libultra/io/vitbl.o(.scommon*);
        build/src/libultra/io/visetevent.o(.scommon*);
        build/src/libultra/io/visetmode.o(.scommon*);
        build/src/libultra/io/visetspecial.o(.scommon*);
        build/src/libultra/io/visetyscale.o(.scommon*);
        build/src/libultra/io/viswapbuf.o(.scommon*);
        build/src/libultra/io/viswapcontext.o(.scommon*);
        build/src/libultra/io/viblack.o(.scommon*);
        build/src/libultra/mgu/mtxident.o(.scommon*);
        build/src/libultra/mgu/mtxidentf.o(.scommon*);
        build/src/libultra/mgu/mtxf2l.o(.scommon*);
        build/src/libultra/mgu/mtxl2f.o(.scommon*);
        build/src/libultra/mgu/mtxcatf.o(.scommon*);
        build/src/libultra/mgu/scale.o(.scommon*);
        build/src/libultra/mgu/scalef.o(.scommon*);
        build/src/libultra/mgu/translate.o(.scommon*);
        build/src/libultra/mgu/translatef.o(.scommon*);
        build/src/libultra/os/initialize.o(.scommon*);
        build/src/libultra/io/conteepread.o(.scommon*);
        build/src/libultra/io/conteepwrite.o(.scommon*);
        build/src/libultra/os/exceptasm.o(.scommon*);
        build/src/libultra/os/interrupt.o(.scommon*);
        build/src/libultra/os/setintmask.o(.scommon*);
        build/src/libultra/os/setglobalintmask.o(.scommon*);
        build/src/libultra/os/resetglobalintmask.o(.scommon*);
        build/src/libultra/io/pirawdma.o(.scommon*);
        build/src/libultra/io/pigetcmdq.o(.scommon*);
        build/src/libultra/io/epirawread.o(.scommon*);
        build/src/libultra/io/epirawwrite.o(.scommon*);
        build/src/libultra/io/ai.o(.scommon*);
        build/src/libultra/audio/drvrnew.o(.scommon*);
        build/src/libultra/audio/load.o(.scommon*);
        build/src/libultra/audio/auxbus.o(.scommon*);
        build/src/libultra/audio/filter.o(.scommon*);
        build/src/libultra/audio/mainbus.o(.scommon*);
        build/src/libultra/audio/resample.o(.scommon*);
        build/src/libultra/audio/reverb.o(.scommon*);
        build/src/libultra/audio/save.o(.scommon*);
        build/src/libultra/audio/heapalloc.o(.scommon*);
        build/src/libultra/audio/copy.o(.scommon*);
        build/src/libultra/os/invalicache.o(.scommon*);
        build/src/libultra/os/writebackdcache.o(.scommon*);
        build/src/libultra/io/dpsetnextbuf.o(.scommon*);
        build/src/libultra/os/getcause.o(.scommon*);
        build/src/libultra/os/getcount.o(.scommon*);
        build/src/libultra/os/getsr.o(.scommon*);
        build/src/libultra/os/setcompare.o(.scommon*);
        build/src/libultra/os/setfpccsr.o(.scommon*);
        build/src/libultra/os/setsr.o(.scommon*);
        build/src/libultra/os/setwatchlo.o(.scommon*);
        build/src/libultra/io/sp.o(.scommon*);
        build/src/libultra/io/spgetstat.o(.scommon*);
        build/src/libultra/io/spsetstat.o(.scommon*);
        build/src/libultra/io/spsetpc.o(.scommon*);
        build/src/libultra/io/sprawdma.o(.scommon*);
        build/src/libultra/io/sirawread.o(.scommon*);
        build/src/libultra/io/sirawwrite.o(.scommon*);
        build/src/libultra/os/destroythread.o(.scommon*);
        build/src/libultra/os/maptlbrdb.o(.scommon*);
        build/src/libultra/os/unmaptlball.o(.scommon*);
        build/src/libultra/io/vi.o(.scommon*);
        build/src/libultra/io/vigetcurrcontext.o(.scommon*);
        build/src/libultra/vimodes/vimodentsclan1.o(.scommon*);
        build/src/libultra/vimodes/vimodepallan1.o(.scommon*);
        build/src/libultra/vimodes/vimodempallan1.o(.scommon*);
        build/src/libultra/os/parameters.o(.scommon*);
        build/src/libultra/gu/libm_vals.o(.scommon*);
        build/src/libultra/io/dp.o(.scommon*);
        build/src/libultra/io/si.o(.scommon*);
        build/src/libkmc/fmod.o(.scommon*);
        build/src/libkmc/memmove.o(.scommon*);
        build/src/libkmc/memset.o(.scommon*);
        build/src/libkmc/modf.o(.scommon*);
        build/src/libkmc/rand.o(.scommon*);
        build/src/libkmc/strcpy.o(.scommon*);
        build/src/libkmc/mmuldi3.o(.scommon*);
        build/src/libkmc/ctype.o(.scommon*);
        . = ALIGN(., 0x10);
        boot_SCOMMON_END = .;
        boot_SCOMMON_SIZE = ABSOLUTE(boot_SCOMMON_END - boot_SCOMMON_START);

        boot_BSS_START = .;
        build/src/boot/boot_main.o(.bss*);
        build/src/boot/util.o(.bss*);
        build/src/libultra/io/conteepprobe.o(.bss*);
        build/src/libultra/io/conteeplongwrite.o(.bss*);
        build/src/libultra/io/conteeplongread.o(.bss*);
        build/src/libultra/io/pimgr.o(.bss*);
        build/src/libultra/io/epirawdma.o(.bss*);
        build/src/libultra/io/epidma.o(.bss*);
        build/src/libultra/io/cartrominit.o(.bss*);
        build/src/libultra/io/devmgr.o(.bss*);
        build/src/libultra/io/piacs.o(.bss*);
        build/src/libultra/io/pidma.o(.bss*);
        build/src/libultra/io/aigetlen.o(.bss*);
        build/src/libultra/io/aigetstat.o(.bss*);
        build/src/libultra/io/aisetfreq.o(.bss*);
        build/src/libultra/io/aisetnextbuf.o(.bss*);
        build/src/libultra/audio/env.o(.bss*);
        build/src/libultra/audio/sl.o(.bss*);
        build/src/libultra/audio/heapinit.o(.bss*);
        build/src/libultra/audio/synthesizer.o(.bss*);
        build/src/libultra/audio/syndelete.o(.bss*);
        build/src/libultra/audio/synaddplayer.o(.bss*);
        build/src/libultra/audio/synallocvoice.o(.bss*);
        build/src/libultra/audio/synstopvoice.o(.bss*);
        build/src/libultra/audio/synstartvoice.o(.bss*);
        build/src/libultra/audio/synsetpitch.o(.bss*);
        build/src/libultra/audio/synsetvol.o(.bss*);
        build/src/libultra/audio/synsetfxmix.o(.bss*);
        build/src/libultra/audio/synsetpan.o(.bss*);
        build/src/libultra/audio/synallocfx.o(.bss*);
        build/src/libultra/os/invaldcache.o(.bss*);
        build/src/libultra/os/writebackdcacheall.o(.bss*);
        build/src/libultra/io/contquery.o(.bss*);
        build/src/libultra/io/contreaddata.o(.bss*);
        build/src/libultra/io/controller.o(.bss*);
        build/src/libultra/io/contsetch.o(.bss*);
        build/src/libultra/os/virtualtophysical.o(.bss*);
        build/src/libultra/gu/sqrtf.o(.bss*);
        build/src/libultra/gu/cosf.o(.bss*);
        build/src/libultra/gu/ortho.o(.bss*);
        build/src/libultra/gu/perspective.o(.bss*);
        build/src/libultra/gu/rotaterpy.o(.bss*);
        build/src/libultra/gu/sinf.o(.bss*);
        build/src/libultra/gu/sins.o(.bss*);
        build/src/libultra/libc/bcmp.o(.bss*);
        build/src/libultra/libc/bcopy.o(.bss*);
        build/src/libultra/libc/bzero.o(.bss*);
        build/src/libultra/libc/string.o(.bss*);
        build/src/libultra/os/createmesgqueue.o(.bss*);
        build/src/libultra/os/jammesg.o(.bss*);
        build/src/libultra/os/recvmesg.o(.bss*);
        build/src/libultra/os/sendmesg.o(.bss*);
        build/src/libultra/os/seteventmesg.o(.bss*);
        build/src/libultra/io/sptask.o(.bss*);
        build/src/libultra/io/sptaskyield.o(.bss*);
        build/src/libultra/io/sptaskyielded.o(.bss*);
        build/src/libultra/sched/sched.o(.bss*);
        build/src/libultra/io/sirawdma.o(.bss*);
        build/src/libultra/io/siacs.o(.bss*);
        build/src/libultra/os/createthread.o(.bss*);
        build/src/libultra/os/getthreadpri.o(.bss*);
        build/src/libultra/os/setthreadpri.o(.bss*);
        build/src/libultra/os/startthread.o(.bss*);
        build/src/libultra/os/stopthread.o(.bss*);
        build/src/libultra/os/thread.o(.bss*);
        build/src/libultra/os/yieldthread.o(.bss*);
        build/src/libultra/os/gettime.o(.bss*);
        build/src/libultra/os/settime.o(.bss*);
        build/src/libultra/os/settimer.o(.bss*);
        build/src/libultra/os/timerintr.o(.bss*);
        build/src/libultra/os/probetlb.o(.bss*);
        build/src/libultra/io/vigetcurrframebuf.o(.bss*);
        build/src/libultra/io/vigetnextframebuf.o(.bss*);
        build/src/libultra/io/vimgr.o(.bss*);
        build/src/libultra/io/vitbl.o(.bss*);
        build/src/libultra/io/visetevent.o(.bss*);
        build/src/libultra/io/visetmode.o(.bss*);
        build/src/libultra/io/visetspecial.o(.bss*);
        build/src/libultra/io/visetyscale.o(.bss*);
        build/src/libultra/io/viswapbuf.o(.bss*);
        build/src/libultra/io/viswapcontext.o(.bss*);
        build/src/libultra/io/viblack.o(.bss*);
        build/src/libultra/mgu/mtxident.o(.bss*);
        build/src/libultra/mgu/mtxidentf.o(.bss*);
        build/src/libultra/mgu/mtxf2l.o(.bss*);
        build/src/libultra/mgu/mtxl2f.o(.bss*);
        build/src/libultra/mgu/mtxcatf.o(.bss*);
        build/src/libultra/mgu/scale.o(.bss*);
        build/src/libultra/mgu/scalef.o(.bss*);
        build/src/libultra/mgu/translate.o(.bss*);
        build/src/libultra/mgu/translatef.o(.bss*);
        build/src/libultra/os/initialize.o(.bss*);
        build/src/libultra/io/conteepread.o(.bss*);
        build/src/libultra/io/conteepwrite.o(.bss*);
        build/src/libultra/os/exceptasm.o(.bss*);
        build/src/libultra/os/interrupt.o(.bss*);
        build/src/libultra/os/setintmask.o(.bss*);
        build/src/libultra/os/setglobalintmask.o(.bss*);
        build/src/libultra/os/resetglobalintmask.o(.bss*);
        build/src/libultra/io/pirawdma.o(.bss*);
        build/src/libultra/io/pigetcmdq.o(.bss*);
        build/src/libultra/io/epirawread.o(.bss*);
        build/src/libultra/io/epirawwrite.o(.bss*);
        build/src/libultra/io/ai.o(.bss*);
        build/src/libultra/audio/drvrnew.o(.bss*);
        build/src/libultra/audio/load.o(.bss*);
        build/src/libultra/audio/auxbus.o(.bss*);
        build/src/libultra/audio/filter.o(.bss*);
        build/src/libultra/audio/mainbus.o(.bss*);
        build/src/libultra/audio/resample.o(.bss*);
        build/src/libultra/audio/reverb.o(.bss*);
        build/src/libultra/audio/save.o(.bss*);
        build/src/libultra/audio/heapalloc.o(.bss*);
        build/src/libultra/audio/copy.o(.bss*);
        build/src/libultra/os/invalicache.o(.bss*);
        build/src/libultra/os/writebackdcache.o(.bss*);
        build/src/libultra/io/dpsetnextbuf.o(.bss*);
        build/src/libultra/os/getcause.o(.bss*);
        build/src/libultra/os/getcount.o(.bss*);
        build/src/libultra/os/getsr.o(.bss*);
        build/src/libultra/os/setcompare.o(.bss*);
        build/src/libultra/os/setfpccsr.o(.bss*);
        build/src/libultra/os/setsr.o(.bss*);
        build/src/libultra/os/setwatchlo.o(.bss*);
        build/src/libultra/io/sp.o(.bss*);
        build/src/libultra/io/spgetstat.o(.bss*);
        build/src/libultra/io/spsetstat.o(.bss*);
        build/src/libultra/io/spsetpc.o(.bss*);
        build/src/libultra/io/sprawdma.o(.bss*);
        build/src/libultra/io/sirawread.o(.bss*);
        build/src/libultra/io/sirawwrite.o(.bss*);
        build/src/libultra/os/destroythread.o(.bss*);
        build/src/libultra/os/maptlbrdb.o(.bss*);
        build/src/libultra/os/unmaptlball.o(.bss*);
        build/src/libultra/io/vi.o(.bss*);
        build/src/libultra/io/vigetcurrcontext.o(.bss*);
        build/src/libultra/vimodes/vimodentsclan1.o(.bss*);
        build/src/libultra/vimodes/vimodepallan1.o(.bss*);
        build/src/libultra/vimodes/vimodempallan1.o(.bss*);
        build/src/libultra/os/parameters.o(.bss*);
        build/src/libultra/gu/libm_vals.o(.bss*);
        build/src/libultra/io/dp.o(.bss*);
        build/src/libultra/io/si.o(.bss*);
        build/src/libkmc/fmod.o(.bss*);
        build/src/libkmc/memmove.o(.bss*);
        build/src/libkmc/memset.o(.bss*);
        build/src/libkmc/modf.o(.bss*);
        build/src/libkmc/rand.o(.bss*);
        build/src/libkmc/strcpy.o(.bss*);
        build/src/libkmc/mmuldi3.o(.bss*);
        build/src/libkmc/ctype.o(.bss*);
        . = ALIGN(., 0x10);
        boot_BSS_END = .;
        boot_BSS_SIZE = ABSOLUTE(boot_BSS_END - boot_BSS_START);

        bootCOMMON_START = .;
        build/src/boot/boot_main.o(COMMON*);
        build/src/boot/util.o(COMMON*);
        build/src/libultra/io/conteepprobe.o(COMMON*);
        build/src/libultra/io/conteeplongwrite.o(COMMON*);
        build/src/libultra/io/conteeplongread.o(COMMON*);
        build/src/libultra/io/pimgr.o(COMMON*);
        build/src/libultra/io/epirawdma.o(COMMON*);
        build/src/libultra/io/epidma.o(COMMON*);
        build/src/libultra/io/cartrominit.o(COMMON*);
        build/src/libultra/io/devmgr.o(COMMON*);
        build/src/libultra/io/piacs.o(COMMON*);
        build/src/libultra/io/pidma.o(COMMON*);
        build/src/libultra/io/aigetlen.o(COMMON*);
        build/src/libultra/io/aigetstat.o(COMMON*);
        build/src/libultra/io/aisetfreq.o(COMMON*);
        build/src/libultra/io/aisetnextbuf.o(COMMON*);
        build/src/libultra/audio/env.o(COMMON*);
        build/src/libultra/audio/sl.o(COMMON*);
        build/src/libultra/audio/heapinit.o(COMMON*);
        build/src/libultra/audio/synthesizer.o(COMMON*);
        build/src/libultra/audio/syndelete.o(COMMON*);
        build/src/libultra/audio/synaddplayer.o(COMMON*);
        build/src/libultra/audio/synallocvoice.o(COMMON*);
        build/src/libultra/audio/synstopvoice.o(COMMON*);
        build/src/libultra/audio/synstartvoice.o(COMMON*);
        build/src/libultra/audio/synsetpitch.o(COMMON*);
        build/src/libultra/audio/synsetvol.o(COMMON*);
        build/src/libultra/audio/synsetfxmix.o(COMMON*);
        build/src/libultra/audio/synsetpan.o(COMMON*);
        build/src/libultra/audio/synallocfx.o(COMMON*);
        build/src/libultra/os/invaldcache.o(COMMON*);
        build/src/libultra/os/writebackdcacheall.o(COMMON*);
        build/src/libultra/io/contquery.o(COMMON*);
        build/src/libultra/io/contreaddata.o(COMMON*);
        build/src/libultra/io/controller.o(COMMON*);
        build/src/libultra/io/contsetch.o(COMMON*);
        build/src/libultra/os/virtualtophysical.o(COMMON*);
        build/src/libultra/gu/sqrtf.o(COMMON*);
        build/src/libultra/gu/cosf.o(COMMON*);
        build/src/libultra/gu/ortho.o(COMMON*);
        build/src/libultra/gu/perspective.o(COMMON*);
        build/src/libultra/gu/rotaterpy.o(COMMON*);
        build/src/libultra/gu/sinf.o(COMMON*);
        build/src/libultra/gu/sins.o(COMMON*);
        build/src/libultra/libc/bcmp.o(COMMON*);
        build/src/libultra/libc/bcopy.o(COMMON*);
        build/src/libultra/libc/bzero.o(COMMON*);
        build/src/libultra/libc/string.o(COMMON*);
        build/src/libultra/os/createmesgqueue.o(COMMON*);
        build/src/libultra/os/jammesg.o(COMMON*);
        build/src/libultra/os/recvmesg.o(COMMON*);
        build/src/libultra/os/sendmesg.o(COMMON*);
        build/src/libultra/os/seteventmesg.o(COMMON*);
        build/src/libultra/io/sptask.o(COMMON*);
        build/src/libultra/io/sptaskyield.o(COMMON*);
        build/src/libultra/io/sptaskyielded.o(COMMON*);
        build/src/libultra/sched/sched.o(COMMON*);
        build/src/libultra/io/sirawdma.o(COMMON*);
        build/src/libultra/io/siacs.o(COMMON*);
        build/src/libultra/os/createthread.o(COMMON*);
        build/src/libultra/os/getthreadpri.o(COMMON*);
        build/src/libultra/os/setthreadpri.o(COMMON*);
        build/src/libultra/os/startthread.o(COMMON*);
        build/src/libultra/os/stopthread.o(COMMON*);
        build/src/libultra/os/thread.o(COMMON*);
        build/src/libultra/os/yieldthread.o(COMMON*);
        build/src/libultra/os/gettime.o(COMMON*);
        build/src/libultra/os/settime.o(COMMON*);
        build/src/libultra/os/settimer.o(COMMON*);
        build/src/libultra/os/timerintr.o(COMMON*);
        build/src/libultra/os/probetlb.o(COMMON*);
        build/src/libultra/io/vigetcurrframebuf.o(COMMON*);
        build/src/libultra/io/vigetnextframebuf.o(COMMON*);
        build/src/libultra/io/vimgr.o(COMMON*);
        build/src/libultra/io/vitbl.o(COMMON*);
        build/src/libultra/io/visetevent.o(COMMON*);
        build/src/libultra/io/visetmode.o(COMMON*);
        build/src/libultra/io/visetspecial.o(COMMON*);
        build/src/libultra/io/visetyscale.o(COMMON*);
        build/src/libultra/io/viswapbuf.o(COMMON*);
        build/src/libultra/io/viswapcontext.o(COMMON*);
        build/src/libultra/io/viblack.o(COMMON*);
        build/src/libultra/mgu/mtxident.o(COMMON*);
        build/src/libultra/mgu/mtxidentf.o(COMMON*);
        build/src/libultra/mgu/mtxf2l.o(COMMON*);
        build/src/libultra/mgu/mtxl2f.o(COMMON*);
        build/src/libultra/mgu/mtxcatf.o(COMMON*);
        build/src/libultra/mgu/scale.o(COMMON*);
        build/src/libultra/mgu/scalef.o(COMMON*);
        build/src/libultra/mgu/translate.o(COMMON*);
        build/src/libultra/mgu/translatef.o(COMMON*);
        build/src/libultra/os/initialize.o(COMMON*);
        build/src/libultra/io/conteepread.o(COMMON*);
        build/src/libultra/io/conteepwrite.o(COMMON*);
        build/src/libultra/os/exceptasm.o(COMMON*);
        build/src/libultra/os/interrupt.o(COMMON*);
        build/src/libultra/os/setintmask.o(COMMON*);
        build/src/libultra/os/setglobalintmask.o(COMMON*);
        build/src/libultra/os/resetglobalintmask.o(COMMON*);
        build/src/libultra/io/pirawdma.o(COMMON*);
        build/src/libultra/io/pigetcmdq.o(COMMON*);
        build/src/libultra/io/epirawread.o(COMMON*);
        build/src/libultra/io/epirawwrite.o(COMMON*);
        build/src/libultra/io/ai.o(COMMON*);
        build/src/libultra/audio/drvrnew.o(COMMON*);
        build/src/libultra/audio/load.o(COMMON*);
        build/src/libultra/audio/auxbus.o(COMMON*);
        build/src/libultra/audio/filter.o(COMMON*);
        build/src/libultra/audio/mainbus.o(COMMON*);
        build/src/libultra/audio/resample.o(COMMON*);
        build/src/libultra/audio/reverb.o(COMMON*);
        build/src/libultra/audio/save.o(COMMON*);
        build/src/libultra/audio/heapalloc.o(COMMON*);
        build/src/libultra/audio/copy.o(COMMON*);
        build/src/libultra/os/invalicache.o(COMMON*);
        build/src/libultra/os/writebackdcache.o(COMMON*);
        build/src/libultra/io/dpsetnextbuf.o(COMMON*);
        build/src/libultra/os/getcause.o(COMMON*);
        build/src/libultra/os/getcount.o(COMMON*);
        build/src/libultra/os/getsr.o(COMMON*);
        build/src/libultra/os/setcompare.o(COMMON*);
        build/src/libultra/os/setfpccsr.o(COMMON*);
        build/src/libultra/os/setsr.o(COMMON*);
        build/src/libultra/os/setwatchlo.o(COMMON*);
        build/src/libultra/io/sp.o(COMMON*);
        build/src/libultra/io/spgetstat.o(COMMON*);
        build/src/libultra/io/spsetstat.o(COMMON*);
        build/src/libultra/io/spsetpc.o(COMMON*);
        build/src/libultra/io/sprawdma.o(COMMON*);
        build/src/libultra/io/sirawread.o(COMMON*);
        build/src/libultra/io/sirawwrite.o(COMMON*);
        build/src/libultra/os/destroythread.o(COMMON*);
        build/src/libultra/os/maptlbrdb.o(COMMON*);
        build/src/libultra/os/unmaptlball.o(COMMON*);
        build/src/libultra/io/vi.o(COMMON*);
        build/src/libultra/io/vigetcurrcontext.o(COMMON*);
        build/src/libultra/vimodes/vimodentsclan1.o(COMMON*);
        build/src/libultra/vimodes/vimodepallan1.o(COMMON*);
        build/src/libultra/vimodes/vimodempallan1.o(COMMON*);
        build/src/libultra/os/parameters.o(COMMON*);
        build/src/libultra/gu/libm_vals.o(COMMON*);
        build/src/libultra/io/dp.o(COMMON*);
        build/src/libultra/io/si.o(COMMON*);
        build/src/libkmc/fmod.o(COMMON*);
        build/src/libkmc/memmove.o(COMMON*);
        build/src/libkmc/memset.o(COMMON*);
        build/src/libkmc/modf.o(COMMON*);
        build/src/libkmc/rand.o(COMMON*);
        build/src/libkmc/strcpy.o(COMMON*);
        build/src/libkmc/mmuldi3.o(COMMON*);
        build/src/libkmc/ctype.o(COMMON*);
        . = ALIGN(., 0x10);
        bootCOMMON_END = .;
        bootCOMMON_SIZE = ABSOLUTE(bootCOMMON_END - bootCOMMON_START);
    }

    boot_noload_VRAM_END = .;
    boot_noload_VRAM_SIZE = ABSOLUTE(boot_noload_VRAM_END - boot_noload_VRAM);
    boot_VRAM_END = .;
    boot_VRAM_SIZE = ABSOLUTE(boot_VRAM_END - boot_VRAM);
    __romPos += SIZEOF(.boot);
    boot_ROM_END = __romPos;
    boot_ROM_SIZE = ABSOLUTE(boot_ROM_END - boot_ROM_START);

    dma_table_ROM_START = __romPos;
    dma_table_VRAM = ADDR(.dma_table);
    dma_table_alloc_VRAM = .;

    .dma_table : AT(dma_table_ROM_START) SUBALIGN(16)
    {
        FILL(0x00000000);
        dma_table_TEXT_START = .;
        build/src/dma_table/dma_table.o(.text*);
        . = ALIGN(., 0x10);
        dma_table_TEXT_END = .;
        dma_table_TEXT_SIZE = ABSOLUTE(dma_table_TEXT_END - dma_table_TEXT_START);

        dma_table_DATA_START = .;
        build/src/dma_table/dma_table.o(.data*);
        . = ALIGN(., 0x10);
        dma_table_DATA_END = .;
        dma_table_DATA_SIZE = ABSOLUTE(dma_table_DATA_END - dma_table_DATA_START);

        dma_table_RODATA_START = .;
        build/src/dma_table/dma_table.o(.rodata*);
        . = ALIGN(., 0x10);
        dma_table_RODATA_END = .;
        dma_table_RODATA_SIZE = ABSOLUTE(dma_table_RODATA_END - dma_table_RODATA_START);

        dma_table_SDATA_START = .;
        build/src/dma_table/dma_table.o(.sdata*);
        . = ALIGN(., 0x10);
        dma_table_SDATA_END = .;
        dma_table_SDATA_SIZE = ABSOLUTE(dma_table_SDATA_END - dma_table_SDATA_START);
    }

    dma_table_alloc_VRAM_END = .;
    dma_table_alloc_VRAM_SIZE = ABSOLUTE(dma_table_alloc_VRAM_END - dma_table_alloc_VRAM);

    dma_table_noload_VRAM = .;

    .dma_table.noload (NOLOAD) : SUBALIGN(16)
    {
        FILL(0x00000000);
        dma_table_SBSS_START = .;
        build/src/dma_table/dma_table.o(.sbss*);
        . = ALIGN(., 0x10);
        dma_table_SBSS_END = .;
        dma_table_SBSS_SIZE = ABSOLUTE(dma_table_SBSS_END - dma_table_SBSS_START);

        dma_table_SCOMMON_START = .;
        build/src/dma_table/dma_table.o(.scommon*);
        . = ALIGN(., 0x10);
        dma_table_SCOMMON_END = .;
        dma_table_SCOMMON_SIZE = ABSOLUTE(dma_table_SCOMMON_END - dma_table_SCOMMON_START);

        dma_table_BSS_START = .;
        build/src/dma_table/dma_table.o(.bss*);
        . = ALIGN(., 0x10);
        dma_table_BSS_END = .;
        dma_table_BSS_SIZE = ABSOLUTE(dma_table_BSS_END - dma_table_BSS_START);

        dma_tableCOMMON_START = .;
        build/src/dma_table/dma_table.o(COMMON*);
        . = ALIGN(., 0x10);
        dma_tableCOMMON_END = .;
        dma_tableCOMMON_SIZE = ABSOLUTE(dma_tableCOMMON_END - dma_tableCOMMON_START);
    }

    dma_table_noload_VRAM_END = .;
    dma_table_noload_VRAM_SIZE = ABSOLUTE(dma_table_noload_VRAM_END - dma_table_noload_VRAM);
    dma_table_VRAM_END = .;
    dma_table_VRAM_SIZE = ABSOLUTE(dma_table_VRAM_END - dma_table_VRAM);
    __romPos += SIZEOF(.dma_table);
    dma_table_ROM_END = __romPos;
    dma_table_ROM_SIZE = ABSOLUTE(dma_table_ROM_END - dma_table_ROM_START);

    main_segment_ROM_START = __romPos;
    main_segment_VRAM = ADDR(.main_segment);
    main_segment_alloc_VRAM = .;

    .main_segment : AT(main_segment_ROM_START) SUBALIGN(16)
    {
        FILL(0x00000000);
        main_segment_TEXT_START = .;
        build/src/main_segment/main.o(.text*);
        build/src/main_segment/nnsched.o(.text*);
        build/src/main_segment/joy.o(.text*);
        build/src/libmus/player.o(.text*);
        build/src/libmus/player_fx.o(.text*);
        build/src/libmus/aud_dma.o(.text*);
        build/src/libmus/aud_sched.o(.text*);
        build/src/libmus/aud_thread.o(.text*);
        build/src/libmus/lib_memory.o(.text*);
        build/src/libmus/aud_samples.o(.text*);
        build/src/rsp/rspboot.o(.text*);
        build/src/rsp/aspMain.o(.text*);
        build/src/rsp/f3dex2.o(.text*);
        build/src/rsp/s2dex.o(.text*);
        . = ALIGN(., 0x10);
        main_segment_TEXT_END = .;
        main_segment_TEXT_SIZE = ABSOLUTE(main_segment_TEXT_END - main_segment_TEXT_START);

        main_segment_DATA_START = .;
        build/src/main_segment/main.o(.data*);
        build/src/main_segment/nnsched.o(.data*);
        build/src/main_segment/joy.o(.data*);
        build/src/libmus/player.o(.data*);
        build/src/libmus/player_fx.o(.data*);
        build/src/libmus/aud_dma.o(.data*);
        build/src/libmus/aud_sched.o(.data*);
        build/src/libmus/aud_thread.o(.data*);
        build/src/libmus/lib_memory.o(.data*);
        build/src/libmus/aud_samples.o(.data*);
        build/src/rsp/rspboot.o(.data*);
        build/src/rsp/aspMain.o(.data*);
        build/src/rsp/f3dex2.o(.data*);
        build/src/rsp/s2dex.o(.data*);
        . = ALIGN(., 0x10);
        main_segment_DATA_END = .;
        main_segment_DATA_SIZE = ABSOLUTE(main_segment_DATA_END - main_segment_DATA_START);

        main_segment_RODATA_START = .;
        build/src/main_segment/main.o(.rodata*);
        build/src/main_segment/nnsched.o(.rodata*);
        build/src/main_segment/joy.o(.rodata*);
        build/src/libmus/player.o(.rodata*);
        build/src/libmus/player_fx.o(.rodata*);
        build/src/libmus/aud_dma.o(.rodata*);
        build/src/libmus/aud_sched.o(.rodata*);
        build/src/libmus/aud_thread.o(.rodata*);
        build/src/libmus/lib_memory.o(.rodata*);
        build/src/libmus/aud_samples.o(.rodata*);
        build/src/rsp/rspboot.o(.rodata*);
        build/src/rsp/aspMain.o(.rodata*);
        build/src/rsp/f3dex2.o(.rodata*);
        build/src/rsp/s2dex.o(.rodata*);
        . = ALIGN(., 0x10);
        main_segment_RODATA_END = .;
        main_segment_RODATA_SIZE = ABSOLUTE(main_segment_RODATA_END - main_segment_RODATA_START);

        main_segment_SDATA_START = .;
        build/src/main_segment/main.o(.sdata*);
        build/src/main_segment/nnsched.o(.sdata*);
        build/src/main_segment/joy.o(.sdata*);
        build/src/libmus/player.o(.sdata*);
        build/src/libmus/player_fx.o(.sdata*);
        build/src/libmus/aud_dma.o(.sdata*);
        build/src/libmus/aud_sched.o(.sdata*);
        build/src/libmus/aud_thread.o(.sdata*);
        build/src/libmus/lib_memory.o(.sdata*);
        build/src/libmus/aud_samples.o(.sdata*);
        build/src/rsp/rspboot.o(.sdata*);
        build/src/rsp/aspMain.o(.sdata*);
        build/src/rsp/f3dex2.o(.sdata*);
        build/src/rsp/s2dex.o(.sdata*);
        . = ALIGN(., 0x10);
        main_segment_SDATA_END = .;
        main_segment_SDATA_SIZE = ABSOLUTE(main_segment_SDATA_END - main_segment_SDATA_START);
    }

    main_segment_alloc_VRAM_END = .;
    main_segment_alloc_VRAM_SIZE = ABSOLUTE(main_segment_alloc_VRAM_END - main_segment_alloc_VRAM);

    main_segment_noload_VRAM = .;

    .main_segment.noload (NOLOAD) : SUBALIGN(16)
    {
        FILL(0x00000000);
        main_segment_SBSS_START = .;
        build/src/main_segment/main.o(.sbss*);
        build/src/main_segment/nnsched.o(.sbss*);
        build/src/main_segment/joy.o(.sbss*);
        build/src/libmus/player.o(.sbss*);
        build/src/libmus/player_fx.o(.sbss*);
        build/src/libmus/aud_dma.o(.sbss*);
        build/src/libmus/aud_sched.o(.sbss*);
        build/src/libmus/aud_thread.o(.sbss*);
        build/src/libmus/lib_memory.o(.sbss*);
        build/src/libmus/aud_samples.o(.sbss*);
        build/src/rsp/rspboot.o(.sbss*);
        build/src/rsp/aspMain.o(.sbss*);
        build/src/rsp/f3dex2.o(.sbss*);
        build/src/rsp/s2dex.o(.sbss*);
        . = ALIGN(., 0x10);
        main_segment_SBSS_END = .;
        main_segment_SBSS_SIZE = ABSOLUTE(main_segment_SBSS_END - main_segment_SBSS_START);

        main_segment_SCOMMON_START = .;
        build/src/main_segment/main.o(.scommon*);
        build/src/main_segment/nnsched.o(.scommon*);
        build/src/main_segment/joy.o(.scommon*);
        build/src/libmus/player.o(.scommon*);
        build/src/libmus/player_fx.o(.scommon*);
        build/src/libmus/aud_dma.o(.scommon*);
        build/src/libmus/aud_sched.o(.scommon*);
        build/src/libmus/aud_thread.o(.scommon*);
        build/src/libmus/lib_memory.o(.scommon*);
        build/src/libmus/aud_samples.o(.scommon*);
        build/src/rsp/rspboot.o(.scommon*);
        build/src/rsp/aspMain.o(.scommon*);
        build/src/rsp/f3dex2.o(.scommon*);
        build/src/rsp/s2dex.o(.scommon*);
        . = ALIGN(., 0x10);
        main_segment_SCOMMON_END = .;
        main_segment_SCOMMON_SIZE = ABSOLUTE(main_segment_SCOMMON_END - main_segment_SCOMMON_START);

        main_segment_BSS_START = .;
        build/src/main_segment/main.o(.bss*);
        build/src/main_segment/nnsched.o(.bss*);
        build/src/main_segment/joy.o(.bss*);
        build/src/libmus/player.o(.bss*);
        build/src/libmus/player_fx.o(.bss*);
        build/src/libmus/aud_dma.o(.bss*);
        build/src/libmus/aud_sched.o(.bss*);
        build/src/libmus/aud_thread.o(.bss*);
        build/src/libmus/lib_memory.o(.bss*);
        build/src/libmus/aud_samples.o(.bss*);
        build/src/rsp/rspboot.o(.bss*);
        build/src/rsp/aspMain.o(.bss*);
        build/src/rsp/f3dex2.o(.bss*);
        build/src/rsp/s2dex.o(.bss*);
        . = ALIGN(., 0x10);
        main_segment_BSS_END = .;
        main_segment_BSS_SIZE = ABSOLUTE(main_segment_BSS_END - main_segment_BSS_START);

        main_segmentCOMMON_START = .;
        build/src/main_segment/main.o(COMMON*);
        build/src/main_segment/nnsched.o(COMMON*);
        build/src/main_segment/joy.o(COMMON*);
        build/src/libmus/player.o(COMMON*);
        build/src/libmus/player_fx.o(COMMON*);
        build/src/libmus/aud_dma.o(COMMON*);
        build/src/libmus/aud_sched.o(COMMON*);
        build/src/libmus/aud_thread.o(COMMON*);
        build/src/libmus/lib_memory.o(COMMON*);
        build/src/libmus/aud_samples.o(COMMON*);
        build/src/rsp/rspboot.o(COMMON*);
        build/src/rsp/aspMain.o(COMMON*);
        build/src/rsp/f3dex2.o(COMMON*);
        build/src/rsp/s2dex.o(COMMON*);
        . = ALIGN(., 0x10);
        main_segmentCOMMON_END = .;
        main_segmentCOMMON_SIZE = ABSOLUTE(main_segmentCOMMON_END - main_segmentCOMMON_START);
    }

    main_segment_noload_VRAM_END = .;
    main_segment_noload_VRAM_SIZE = ABSOLUTE(main_segment_noload_VRAM_END - main_segment_noload_VRAM);
    main_segment_VRAM_END = .;
    main_segment_VRAM_SIZE = ABSOLUTE(main_segment_VRAM_END - main_segment_VRAM);
    __romPos += SIZEOF(.main_segment);
    main_segment_ROM_END = __romPos;
    main_segment_ROM_SIZE = ABSOLUTE(main_segment_ROM_END - main_segment_ROM_START);

    framebuffer_ROM_START = __romPos;
    framebuffer_VRAM = ADDR(.framebuffer);
    framebuffer_alloc_VRAM = .;

    .framebuffer 0x803B5000 : AT(framebuffer_ROM_START) SUBALIGN(16)
    {
        FILL(0x00000000);
        framebuffer_TEXT_START = .;
        build/src/buffers/framebuffer.o(.text*);
        . = ALIGN(., 0x10);
        framebuffer_TEXT_END = .;
        framebuffer_TEXT_SIZE = ABSOLUTE(framebuffer_TEXT_END - framebuffer_TEXT_START);

        framebuffer_DATA_START = .;
        build/src/buffers/framebuffer.o(.data*);
        . = ALIGN(., 0x10);
        framebuffer_DATA_END = .;
        framebuffer_DATA_SIZE = ABSOLUTE(framebuffer_DATA_END - framebuffer_DATA_START);

        framebuffer_RODATA_START = .;
        build/src/buffers/framebuffer.o(.rodata*);
        . = ALIGN(., 0x10);
        framebuffer_RODATA_END = .;
        framebuffer_RODATA_SIZE = ABSOLUTE(framebuffer_RODATA_END - framebuffer_RODATA_START);

        framebuffer_SDATA_START = .;
        build/src/buffers/framebuffer.o(.sdata*);
        . = ALIGN(., 0x10);
        framebuffer_SDATA_END = .;
        framebuffer_SDATA_SIZE = ABSOLUTE(framebuffer_SDATA_END - framebuffer_SDATA_START);
    }

    framebuffer_alloc_VRAM_END = .;
    framebuffer_alloc_VRAM_SIZE = ABSOLUTE(framebuffer_alloc_VRAM_END - framebuffer_alloc_VRAM);

    framebuffer_noload_VRAM = .;

    .framebuffer.noload (NOLOAD) : SUBALIGN(16)
    {
        FILL(0x00000000);
        framebuffer_SBSS_START = .;
        build/src/buffers/framebuffer.o(.sbss*);
        . = ALIGN(., 0x10);
        framebuffer_SBSS_END = .;
        framebuffer_SBSS_SIZE = ABSOLUTE(framebuffer_SBSS_END - framebuffer_SBSS_START);

        framebuffer_SCOMMON_START = .;
        build/src/buffers/framebuffer.o(.scommon*);
        . = ALIGN(., 0x10);
        framebuffer_SCOMMON_END = .;
        framebuffer_SCOMMON_SIZE = ABSOLUTE(framebuffer_SCOMMON_END - framebuffer_SCOMMON_START);

        framebuffer_BSS_START = .;
        build/src/buffers/framebuffer.o(.bss*);
        . = ALIGN(., 0x10);
        framebuffer_BSS_END = .;
        framebuffer_BSS_SIZE = ABSOLUTE(framebuffer_BSS_END - framebuffer_BSS_START);

        framebufferCOMMON_START = .;
        build/src/buffers/framebuffer.o(COMMON*);
        . = ALIGN(., 0x10);
        framebufferCOMMON_END = .;
        framebufferCOMMON_SIZE = ABSOLUTE(framebufferCOMMON_END - framebufferCOMMON_START);
    }

    framebuffer_noload_VRAM_END = .;
    framebuffer_noload_VRAM_SIZE = ABSOLUTE(framebuffer_noload_VRAM_END - framebuffer_noload_VRAM);
    framebuffer_VRAM_END = .;
    framebuffer_VRAM_SIZE = ABSOLUTE(framebuffer_VRAM_END - framebuffer_VRAM);
    __romPos += SIZEOF(.framebuffer);
    framebuffer_ROM_END = __romPos;
    framebuffer_ROM_SIZE = ABSOLUTE(framebuffer_ROM_END - framebuffer_ROM_START);

    .shstrtab 0 :
    {
        *(.shstrtab);
    }

    /DISCARD/ :
    {
        *(.reginfo);
        *(.MIPS.abiflags);
        *(.MIPS.options);
        *(.note.gnu.build-id);
        *(.interp);
        *(.eh_frame);
        *(*);
    }
}
